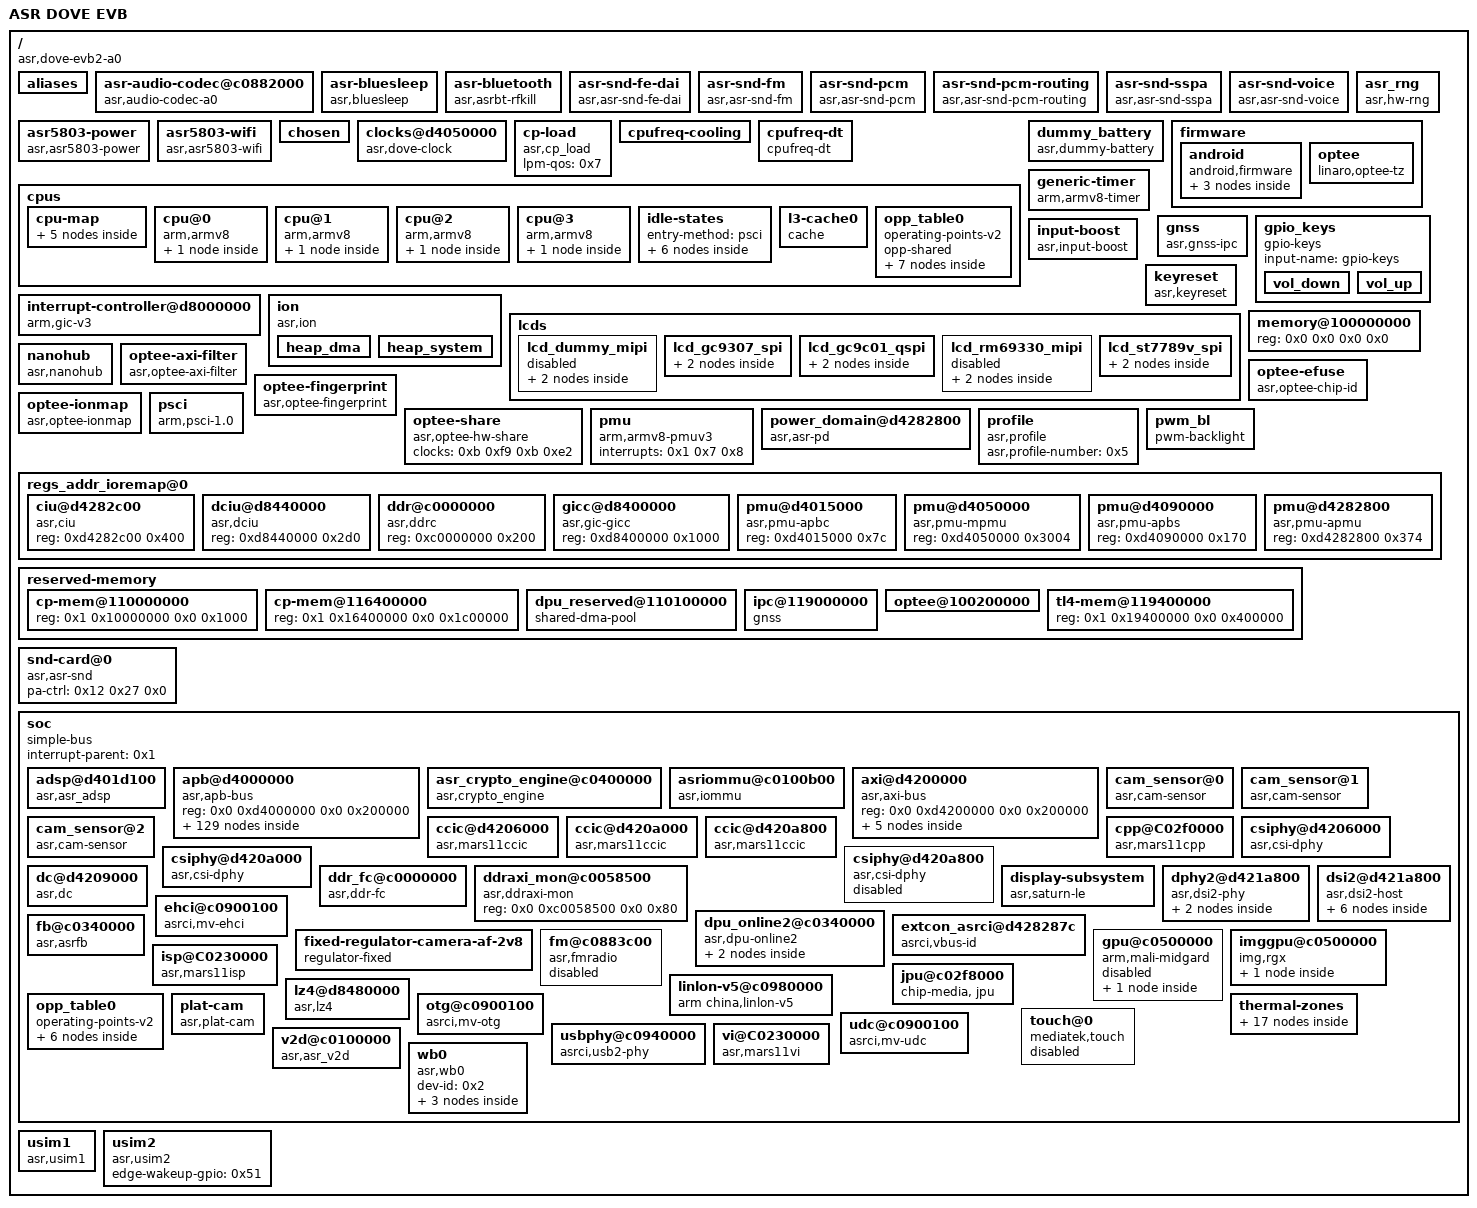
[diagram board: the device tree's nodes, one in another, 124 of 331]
/dts-v1/;

/ {
	#address-cells = <0x2>;
	#size-cells = <0x2>;
	board_id = <0x10000>;
	board_rev = <0x10081>;
	compatible = "asr,dove-evb2-a0", "asr,dove";
	interrupt-parent = <0x1>;
	model = "ASR DOVE EVB";

	aliases {
		i2c0 = "/soc/apb@d4000000/i2c@d4011000";
		i2c1 = "/soc/apb@d4000000/i2c@d4010800";
		i2c3 = "/soc/apb@d4000000/i2c@d4018800";
		serial0 = "/soc/apb@d4000000/uart@d4017000";
		serial1 = "/soc/apb@d4000000/uart@d4018000";
		serial2 = "/soc/apb@d4000000/uart@d4017800";
		serial3 = "/soc/apb@d4000000/uart@d4024000";
	};

	asr-audio-codec@c0882000 {
		compatible = "asr,audio-codec-a0", "syscon";
		interrupt-names = "hook_key", "jack_plug";
		interrupts = <0x0 0x6e 0x4 0x0 0x6f 0x4>;
		reg = <0x0 0xc0882000 0x0 0x21c 0x0 0xc088c000 0x0 0x100>;
		reg-names = "codec_ctrl", "aud_pmu";
		status = "ok";
	};

	asr-bluesleep {
		bluetooth-uart = <0x1>;
		bt_ext_wake = <0x12 0x7a 0x0>;
		bt_host_wake = <0x12 0x72 0x0>;
		compatible = "asr,bluesleep";
		status = "ok";
	};

	asr-bluetooth {
		compatible = "asr,asrbt-rfkill";
		status = "ok";
	};

	asr-snd-fe-dai {
		compatible = "asr,asr-snd-fe-dai";
	};

	asr-snd-fm {
		compatible = "asr,asr-snd-fm";
	};

	asr-snd-pcm {
		compatible = "asr,asr-snd-pcm";
	};

	asr-snd-pcm-routing {
		compatible = "asr,asr-snd-pcm-routing";
	};

	asr-snd-sspa {
		compatible = "asr,asr-snd-sspa";
	};

	asr-snd-voice {
		compatible = "asr,asr-snd-voice";
	};

	asr5803-power {
		bt_ldo_en_gpio = <0x73>;
		bt_wifi_reset = <0x12 0x6a 0x0>;
		compatible = "asr,asr5803-power";
		host_wake_bt_gpio = <0x7a>;
		ldo_1v2-supply = <0x48>;
		status = "ok";
		vldo11_wibpa_1v8-supply = <0x47>;
		wifi_host_wake_wlan = <0x6e>;
		wifi_ldo_en_gpio = <0x6f>;
	};

	asr5803-wifi {
		asr,is_dcs_mode = <0x1>;
		asr,is_dcxo_mode = <0x1>;
		compatible = "asr,asr5803-wifi";
		mac-address = [00 00 00 00 00 00];
		status = "ok";
	};

	asr_rng {
		compatible = "asr,hw-rng";
		status = "ok";
	};

	chosen {
		bootargs = "earlycon clk_ignore_unused log_buf_len=1M cma=16M@0x110400000 uart_dma printk.devkmsg=on";
		stdout-path = "serial0:115200n8";
	};

	clocks@d4050000 {
		#clock-cells = <0x1>;
		asr,keep_dbgclk_on;
		booton-clks = <0x28 0x3f>;
		compatible = "asr,dove-clock";
		interrupts = <0x0 0x60 0x4>;
		phandle = <0xb>;
		reg = <0x0 0xd4050000 0x0 0x209c 0x0 0xd4282800 0x0 0x400 0x0 0xd4015000 0x0 0x1000 0x0 0xd4090000 0x0 0x1000 0x0 0xd4282c00 0x0 0x400 0x0 0xd8440000 0x0 0x98 0x0 0xc0000000 0x0 0x4280>;
		reg-names = "mpmu", "apmu", "apbc", "apbs", "ciu", "dciu", "ddrc";
	};

	cp-load {
		compatible = "asr,cp_load";
		lpm-qos = <0x7>;
		status = "okay";
	};

	cpufreq-cooling {
		status = "ok";
	};

	cpufreq-dt {
		compatible = "cpufreq-dt";
		status = "okay";
	};

	cpus {
		#address-cells = <0x2>;
		#size-cells = <0x0>;

		cpu-map {

			cluster0 {

				core0 {
					cpu = <0x2>;
				};

				core1 {
					cpu = <0x3>;
				};

				core2 {
					cpu = <0x4>;
				};

				core3 {
					cpu = <0x5>;
				};
			};
		};

		cpu@0 {
			#cooling-cells = <0x2>;
			capacity-dmips-mhz = <0x400>;
			clocks = <0xb 0xb6>;
			compatible = "arm,armv8";
			cpu-idle-states = <0x6 0x7 0x8 0x9 0xa>;
			device_type = "cpu";
			dynamic-power-coefficient = <0x78>;
			enable-method = "psci";
			next-level-cache = <0xd>;
			operating-points-v2 = <0xc>;
			phandle = <0x2>;
			reg = <0x0 0x0>;

			l2-cache {
				next-level-cache = <0xe>;
				phandle = <0xd>;
			};
		};

		cpu@1 {
			#cooling-cells = <0x2>;
			capacity-dmips-mhz = <0x400>;
			clocks = <0xb 0xb6>;
			compatible = "arm,armv8";
			cpu-idle-states = <0x6 0x7 0x8 0x9 0xa>;
			device_type = "cpu";
			dynamic-power-coefficient = <0x78>;
			enable-method = "psci";
			next-level-cache = <0xf>;
			operating-points-v2 = <0xc>;
			phandle = <0x3>;
			reg = <0x0 0x100>;

			l2-cache {
				next-level-cache = <0xe>;
				phandle = <0xf>;
			};
		};

		cpu@2 {
			#cooling-cells = <0x2>;
			capacity-dmips-mhz = <0x400>;
			clocks = <0xb 0xb6>;
			compatible = "arm,armv8";
			cpu-idle-states = <0x6 0x7 0x8 0x9 0xa>;
			device_type = "cpu";
			dynamic-power-coefficient = <0x78>;
			enable-method = "psci";
			next-level-cache = <0x10>;
			operating-points-v2 = <0xc>;
			phandle = <0x4>;
			reg = <0x0 0x200>;

			l2-cache {
				next-level-cache = <0xe>;
				phandle = <0x10>;
			};
		};

		cpu@3 {
			#cooling-cells = <0x2>;
			capacity-dmips-mhz = <0x400>;
			clocks = <0xb 0xb6>;
			compatible = "arm,armv8";
			cpu-idle-states = <0x6 0x7 0x8 0x9 0xa>;
			device_type = "cpu";
			dynamic-power-coefficient = <0x78>;
			enable-method = "psci";
			next-level-cache = <0x11>;
			operating-points-v2 = <0xc>;
			phandle = <0x5>;
			reg = <0x0 0x300>;

			l2-cache {
				next-level-cache = <0xe>;
				phandle = <0x11>;
			};
		};

		idle-states {
			entry-method = "psci";

			chip-d1 {
				arm,psci-suspend-param = <0x2010455>;
				compatible = "arm,idle-state";
				entry-latency-us = <0x1f4>;
				exit-latency-us = <0x1f4>;
				local-timer-stop;
				min-residency-us = <0x7d0>;
				phandle = <0x9>;
				wakeup-latency-us = <0x3e8>;
			};

			chip-d1p {
				arm,psci-suspend-param = <0x2010355>;
				compatible = "arm,idle-state";
				entry-latency-us = <0x12c>;
				exit-latency-us = <0x12c>;
				local-timer-stop;
				min-residency-us = <0x4b0>;
				phandle = <0x8>;
				wakeup-latency-us = <0x258>;
			};

			chip-d2 {
				arm,psci-suspend-param = <0x2010555>;
				compatible = "arm,idle-state";
				entry-latency-us = <0x3e8>;
				exit-latency-us = <0x3e8>;
				local-timer-stop;
				min-residency-us = <0xfa0>;
				phandle = <0xa>;
				wakeup-latency-us = <0x7d0>;
			};

			cluster-mp2 {
				arm,psci-suspend-param = <0x1010055>;
				compatible = "arm,idle-state";
				entry-latency-us = <0xf0>;
				exit-latency-us = <0xf0>;
				local-timer-stop;
				min-residency-us = <0x3c0>;
				phandle = <0x7>;
				wakeup-latency-us = <0x1e0>;
			};

			cpu-c1 {
				arm,psci-suspend-param = <0x2>;
				compatible = "arm,idle-state";
				entry-latency-us = <0x19>;
				exit-latency-us = <0x19>;
				min-residency-us = <0x64>;
			};

			cpu-c2 {
				arm,psci-suspend-param = <0x10005>;
				compatible = "arm,idle-state";
				entry-latency-us = <0x5a>;
				exit-latency-us = <0x5a>;
				local-timer-stop;
				min-residency-us = <0x168>;
				phandle = <0x6>;
			};
		};

		l3-cache0 {
			compatible = "cache";
			phandle = <0xe>;
		};

		opp_table0 {
			compatible = "operating-points-v2";
			opp-shared;
			phandle = <0xc>;

			opp1000000000 {
				clock-latency-ns = <0x30d40>;
				opp-hz = <0x0 0x3b9aca00>;
				opp-microvolt = <0x16e360>;
			};

			opp1228000000 {
				clock-latency-ns = <0x30d40>;
				opp-hz = <0x0 0x4931cb00>;
				opp-microvolt = <0x16e360>;
			};

			opp1500000000 {
				clock-latency-ns = <0x30d40>;
				opp-hz = <0x0 0x59682f00>;
				opp-microvolt = <0x16e360>;
			};

			opp409000000 {
				clock-latency-ns = <0x30d40>;
				opp-hz = <0x0 0x1860d840>;
				opp-microvolt = <0xf4240>;
			};

			opp491000000 {
				clock-latency-ns = <0x30d40>;
				opp-hz = <0x0 0x1d4410c0>;
				opp-microvolt = <0xf4240>;
			};

			opp614000000 {
				clock-latency-ns = <0x30d40>;
				opp-hz = <0x0 0x2498e580>;
				opp-microvolt = <0x16e360>;
			};

			opp819000000 {
				clock-latency-ns = <0x30d40>;
				opp-hz = <0x0 0x30d0f2c0>;
				opp-microvolt = <0x16e360>;
			};
		};
	};

	dummy_battery {
		#cooling-cells = <0x2>;
		compatible = "asr,dummy-battery";
		status = "ok";
	};

	firmware {

		android {
			compatible = "android,firmware";

			fstab {
				compatible = "android,fstab";

				system {
					compatible = "android,system";
					dev = "/dev/block/platform/soc/d4200000.axi/d4281000.sdh/by-name/system";
					fsmgr_flags = "wait";
					mnt_flags = "ro,barrier=1";
					type = "ext4";
				};

				vendor {
					compatible = "android,vendor";
					dev = "/dev/block/platform/soc/d4200000.axi/d4281000.sdh/by-name/vendor";
					fsmgr_flags = "wait";
					mnt_flags = "ro,barrier=1";
					type = "ext4";
				};
			};
		};

		optee {
			compatible = "linaro,optee-tz";
			interrupts = <0x0 0x7d 0x4>;
			method = "smc";
		};
	};

	generic-timer {
		arm,no-tick-in-suspend;
		clock-frequency = <0x18cba80>;
		compatible = "arm,armv8-timer";
		interrupts = <0x1 0xd 0x8 0x1 0xe 0x8 0x1 0xb 0x8 0x1 0xa 0x8>;
	};

	gnss {
		clock-names = "ap2gnss_clk";
		clocks = <0xb 0x12a>;
		compatible = "asr,gnss-ipc";
		interrupt-names = "gnss_ipc", "gnss_wdt", "gnss_hostwake";
		interrupts = <0x0 0x32 0x4 0x0 0x65 0x4 0x0 0x66 0x4>;
		lna_1v8-supply = <0x42>;
		memory-region = <0x40>;
		reg = <0x0 0xd4282800 0x0 0x3bc 0x0 0xd6200000 0x0 0xfc 0x0 0xd401d200 0x0 0x14 0x0 0xd4015000 0x0 0x9c 0x0 0xd6000000 0x0 0x80000>;
		status = "ok";
		tcxo_1v8-supply = <0x41>;
	};

	gpio_keys {
		compatible = "gpio-keys";
		input-name = "gpio-keys";
		status = "ok";

		vol_down {
			debounce-interval = <0xf>;
			gpios = <0x12 0x3a 0x1>;
			label = "volume_down";
			linux,code = <0x72>;
			linux,input-type = <0x1>;
		};

		vol_up {
			debounce-interval = <0xf>;
			gpios = <0x12 0x39 0x1>;
			label = "volume_up";
			linux,code = <0x73>;
			linux,input-type = <0x1>;
		};
	};

	input-boost {
		compatible = "asr,input-boost";
		status = "okay";
	};

	interrupt-controller@d8000000 {
		#address-cells = <0x2>;
		#interrupt-cells = <0x3>;
		#size-cells = <0x2>;
		compatible = "arm,gic-v3";
		interrupt-controller;
		interrupts = <0x1 0x9 0x8>;
		phandle = <0x1>;
		reg = <0x0 0xd8000000 0x0 0x200000 0x0 0xd8080000 0x0 0x200000>;
	};

	ion {
		compatible = "asr,ion";

		heap_dma {
			heap-id = <0x4>;
			heap-name = "dma";
			heap-type = "ion_dma";
		};

		heap_system {
			heap-id = <0x0>;
			heap-name = "system";
			heap-type = "ion_system";
		};
	};

	keyreset {
		compatible = "asr,keyreset";
		keyreset-need-panic;
		keys-down = <0x74 0x73 0x72>;
		status = "okay";
	};

	lcds {
		status = "ok";

		lcd_dummy_mipi {
			burst-mode = <0x2>;
			dsi-color-format = "rgb888";
			dsi-lane-number = <0x4>;
			dsi-work-mode = <0x1>;
			eotp-enable = <0x0>;
			esd-check-enable = <0x0>;
			fps = <0x3c>;
			hbp = <0x64>;
			height = <0x640>;
			height-mm = <0x7e>;
			hfp = <0x63>;
			hsync = <0x4>;
			lane-number = <0x4>;
			phy-bit-clock = <0xde698>;
			phy-escape-clock = <0xcb20>;
			phy-freq = <0x98580>;
			rgb-mode = <0x3>;
			split-enable = <0x0>;
			status = "disabled";
			use-dcs-write;
			vbp = <0x1c>;
			vfp = <0x8c>;
			vsync = <0x6>;
			width = <0x2d0>;
			width-mm = <0x48>;
			work-mode = <0x0>;

			display-timings {

				timing0 {
					clock-frequency = <0x5dc0000>;
					hactive = <0x2d0>;
					hback-porch = <0x64>;
					hfront-porch = <0x63>;
					hsync-active = <0x1>;
					hsync-len = <0x4>;
					vactive = <0x640>;
					vback-porch = <0x1c>;
					vfront-porch = <0x8c>;
					vsync-active = <0x1>;
					vsync-len = <0x6>;
				};
			};
		};

		lcd_gc9307_spi {
			bg-color = <0xff>;
			cmd-initial-0 = [00 01 fe 00 00 01 ef 00 00 01 36 01 48 00 01 3a 01 05 00 01 86 01 98 00 01 89 01 03 00 01 8b 01 80 00 01 8d 01 22 00 01 8e 01 0f 00 01 e8 02 10 40 00 01 ff 01 62 00 01 99 01 3e 00 01 9d 01 4b 00 01 c3 01 34 00 01 c4 01 34 00 01 c9 01 2a 00 01 f0 06 87 08 09 08 06 29 00 01 f2 06 87 08 09 08 06 29 00 01 f1 06 c0 89 6a 3c fe 3f 00 01 f3 06 c0 89 6a 3c fe 3f 00 01 35 01 00 00 01 44 02 00 0a 78 01 11 00 00 01 29 00 14 01 2c 00];
			cmd-initial-1 = [00 01 fe 00 00 01 ef 00 00 01 36 01 48 00 01 3a 01 05 00 01 86 01 98 00 01 89 01 03 00 01 8b 01 80 00 01 8d 01 22 00 01 8e 01 0f 00 01 e8 02 20 40 00 01 ff 01 62 00 01 99 01 3e 00 01 9d 01 4b 00 01 c3 01 34 00 01 c4 01 34 00 01 c9 01 2a 00 01 f0 06 87 08 09 08 06 29 00 01 f2 06 87 08 09 08 06 29 00 01 f1 06 c0 89 6a 3c fe 3f 00 01 f3 06 c0 89 6a 3c fe 3f 00 01 35 01 00 00 01 44 02 00 1a 78 01 11 00 00 01 29 00 14 01 2c 00];
			cmd-initial-2 = [00 01 fe 00 00 01 ef 00 00 01 36 01 48 00 01 35 01 00 00 01 3a 01 05 00 01 86 01 98 00 01 89 01 13 00 01 8b 01 80 00 01 8d 01 33 00 01 8e 01 0f 00 01 ec 03 33 07 af 00 01 c9 01 05 00 01 e8 02 13 17 00 01 c3 01 10 00 01 c4 01 10 00 01 ff 01 62 00 01 99 01 3e 00 01 9d 01 4b 00 01 98 01 3e 00 01 9c 01 4b 00 01 f0 06 c7 08 08 08 05 2e 00 01 f2 06 c7 08 08 08 05 2e 00 01 f1 06 45 8f 6f 33 36 4f 00 01 f3 06 45 8f 6f 33 36 4f 00 01 44 02 00 0a 78 01 11 00 00 01 29 00 14 01 2c 00];
			cmd-initial-3 = [00 01 fe 00 00 01 ef 00 00 01 36 01 48 00 01 35 01 00 00 01 3a 01 05 00 01 86 01 98 00 01 89 01 33 00 01 8b 01 80 00 01 8d 01 33 00 01 8e 01 0f 00 01 ec 03 33 0c d1 00 01 c9 01 16 00 01 e8 02 12 00 00 01 c3 01 14 00 01 c4 01 08 00 01 ff 01 62 00 01 99 01 3e 00 01 9d 01 4b 00 01 98 01 3e 00 01 9c 01 4b 00 01 f0 06 c3 05 08 07 04 26 00 01 f2 06 c3 05 08 07 04 26 00 01 f1 06 3f 7f 6f 35 36 4f 00 01 f3 06 3f 7f 6f 35 36 4f 00 01 44 02 00 0a 78 01 11 00 00 01 29 00 14 01 2c 00];
			cmd-initial-4 = [00 01 fe 00 00 01 ef 00 00 01 36 01 48 00 01 3a 01 05 00 01 35 01 00 00 01 86 01 98 00 01 89 01 13 00 01 8b 01 80 00 01 8d 01 33 00 01 8e 01 0f 00 01 ec 03 33 07 af 00 01 c9 01 05 00 01 e8 02 13 17 00 01 c3 01 10 00 01 c4 01 10 00 01 ff 01 62 00 01 99 01 3e 00 01 9d 01 4b 00 01 98 01 3e 00 01 9c 01 4b 00 01 f0 06 c7 08 08 08 05 2e 00 01 f1 06 45 8f 6f 33 36 4f 00 01 f2 06 c7 08 08 08 05 2e 00 01 f3 06 45 8f 6f 33 36 4f 00 01 44 02 00 0a 78 01 11 00 00 01 29 00 00 01 2c 00];
			cmd-initial-5 = [00 01 fe 00 00 01 ef 00 00 01 36 01 48 00 01 3a 01 05 00 01 86 01 98 00 01 89 01 03 00 01 8b 01 80 00 01 8d 01 22 00 01 8e 01 0f 00 01 e8 02 12 00 00 01 c3 01 47 00 01 c4 01 28 00 01 c9 01 08 00 01 ff 01 62 00 01 99 01 3e 00 01 9d 01 4b 00 01 f0 06 07 0b 0c 0a 06 31 00 01 f2 06 07 07 04 06 06 21 00 01 f1 06 4a 78 76 33 2f af 00 01 f3 06 38 74 72 22 28 6f 00 01 35 01 00 00 01 44 02 00 0a 00 01 11 00 00 01 29 00 00 01 2c 00];
			cmd-initial-6 = [00 01 fe 00 00 01 ef 00 00 01 36 01 48 00 01 3a 01 05 00 01 86 01 98 00 01 89 01 33 00 01 8b 01 80 00 01 8d 01 33 00 01 8e 01 0f 00 01 ec 03 33 0c d1 00 01 c9 01 16 00 01 e8 02 13 17 00 01 c3 01 22 00 01 c4 01 16 00 01 ff 01 62 00 01 99 01 3e 00 01 9d 01 4b 00 01 98 01 3e 00 01 9c 01 4b 00 01 f0 06 c3 05 08 07 04 26 00 01 f2 06 c3 05 08 07 04 26 00 01 f1 06 3f 7f 6f 35 36 4f 00 01 f3 06 3f 7f 6f 35 36 4f 00 01 35 01 00 00 01 44 02 00 0a 78 01 11 00 00 01 29 00 14 01 2c 00];
			cmd-read-id = [00 01 da 01 00 00 01 db 01 93 00 01 dc 01 07 00 01 04 03 07 93 00];
			cmd-set-window-240x240 = <0x12a04 0xef 0x12b04 0xef 0x12c00>;
			cmd-set-window-240x280 = <0x12a04 0xef 0x12b04 0x13012b 0x12c00>;
			cmd-set-window-240x284 = <0x12a04 0xef 0x12b04 0x11b 0x12c00>;
			cmd-set-window-240x296 = <0x12a04 0xef 0x12b04 0x127 0x12c00>;
			cmd-set-window-240x320 = <0x12a04 0xef 0x12b04 0x13f 0x12c00>;
			cmd-sleep-in = <0x14012800 0x78011000>;
			cmd-sleep-out = <0x78011100 0x78012900>;
			custom-cmd-set-window = <0x0>;
			data-lane-number = <0x1>;
			device-id = <0x0>;
			endian = <0x1>;
			format = "rgb565";
			height-mm = <0x7e>;
			interface-id = <0x1>;
			line-number = <0x4>;
			mclk-freq = <0x124f8000>;
			reset-sequence = <0x140178>;
			sample-edge = <0x0>;
			spi-rclk-freq = <0x177000>;
			spi-wclk-freq = <0x3197500>;
			te-en = <0x1>;
			te-polarity = <0x0>;
			width-mm = <0x48>;

			display-timings {

				timing0 {
					clock-frequency = <0x4a6214>;
					hactive = <0xf0>;
					hback-porch = <0x64>;
					hfront-porch = <0x63>;
					hsync-active = <0x1>;
					hsync-len = <0x4>;
					vactive = <0xf0>;
					vback-porch = <0x8>;
					vfront-porch = <0x8>;
					vsync-active = <0x1>;
					vsync-len = <0x6>;
				};
			};
		};

		lcd_gc9c01_qspi {
			bg-color = <0xff>;
			cmd-initial = [00 04 02 00 fe 00 00 00 04 02 00 ef 00 00 00 04 02 00 80 00 01 11 00 04 02 00 81 00 01 70 00 04 02 00 82 00 01 09 00 04 02 00 83 00 01 03 00 04 02 00 84 00 01 20 00 04 02 00 89 00 01 10 00 04 02 00 8a 00 01 4f 00 04 02 00 8b 00 01 08 00 04 02 00 8c 00 01 59 00 04 02 00 8d 00 01 51 00 04 02 00 36 00 01 00 00 04 02 00 3a 00 01 05 00 04 02 00 ec 00 01 77 00 04 02 00 74 00 06 01 80 00 00 00 00 00 04 02 00 98 00 01 3e 00 04 02 00 99 00 01 3e 00 04 02 00 c3 00 01 3a 00 04 02 00 c4 00 01 16 00 04 02 00 a1 00 02 01 04 00 04 02 00 a2 00 02 01 04 00 04 02 00 cb 00 01 02 00 04 02 00 7c 00 02 b6 26 00 04 02 00 ac 00 01 24 00 04 02 00 f6 00 01 80 00 04 02 00 b5 00 02 09 09 00 04 02 00 60 00 04 38 0b 5b 56 00 04 02 00 63 00 04 3a e0 5b 56 00 04 02 00 64 00 06 38 0d 72 dd 5b 56 00 04 02 00 66 00 06 38 11 72 e1 5b 56 00 04 02 00 68 00 07 3b 08 08 00 08 29 5b 00 04 02 00 6e 00 20 00 00 00 07 01 13 11 0b 09 16 15 1d 1e 00 00 00 00 00 00 1e 1d 15 16 0a 0c 12 14 02 08 00 00 00 00 04 02 00 be 00 01 11 00 04 02 00 6c 00 07 cc 0c cc 84 cc 04 50 00 04 02 00 7d 00 01 72 00 04 02 00 7e 00 01 38 00 04 02 00 70 00 0a 02 03 09 05 0c 06 09 05 0c 06 00 04 02 00 90 00 04 06 06 05 06 00 04 02 00 93 00 03 45 ff 00 00 04 02 00 f0 00 06 46 0b 0f 0a 10 3f 00 04 02 00 f1 00 06 52 9a 4f 36 37 ff 00 04 02 00 f2 00 06 46 0b 0f 0a 10 3f 00 04 02 00 f3 00 06 52 9a 4f 36 37 ff 00 04 02 00 35 00 01 00 00 04 02 00 44 00 02 00 25 00 04 02 00 b4 00 02 0a 50 00 04 02 00 fb 00 02 00 00 78 04 02 00 11 00 00 14 04 02 00 29 00 00];
			cmd-set-window = [00 04 02 00 2a 00 04 00 00 01 67 00 04 02 00 2b 00 04 00 00 01 67];
			cmd-sleep-in = [78 04 02 00 28 00 00 96 04 02 00 10 00 00];
			cmd-sleep-out = [78 04 02 00 11 00 00 64 04 02 00 29 00 00];
			cmd-start = [00 04 32 00 2c 00 00];
			data-lane-number = <0x1>;
			device-id = <0x0>;
			endian = <0x1>;
			format = "rgb565";
			frame-sync;
			height-mm = <0x7e>;
			interface-id = <0x1>;
			line-number = <0x4>;
			mclk-freq = <0x124f8000>;
			qspi;
			reset-sequence = [01 78 00 64 01 78];
			sample-edge = <0x0>;
			spi-rclk-freq = <0x177000>;
			spi-wclk-freq = <0x30d4000>;
			te-en = <0x0>;
			te-polarity = <0x0>;
			width-mm = <0x48>;

			display-timings {

				timing0 {
					clock-frequency = <0x3197500>;
					hactive = <0x168>;
					hback-porch = <0x64>;
					hfront-porch = <0x63>;
					hsync-active = <0x1>;
					hsync-len = <0x4>;
					vactive = <0x168>;
					vback-porch = <0x8>;
					vfront-porch = <0x8>;
					vsync-active = <0x1>;
					vsync-len = <0x6>;
				};
			};
		};

		lcd_rm69330_mipi {
			backlight = <0x43>;
			bit-clk = <0x13de4355 0x13de4355>;
			burst-mode = <0x2>;
			dsi-color-format = "rgb888";
			dsi-lane-number = <0x1>;
			dsi-work-mode = <0x0>;
			eotp-enable = <0x0>;
			esd-check-enable = <0x0>;
			fps = <0x3c>;
			hbp = <0x28>;
			height = <0x1c6>;
			height-mm = <0x7e>;
			hfp = <0x14>;
			hsync = <0xa>;
			initial-command = <0x15010002 0xfe071501 0x21504 0x15010002 0xfe001501 0x23500 0x15010002 0x3a771501 0x25100 0x39010005 0x2a000e01 0xd3390100 0x52b0000 0x1c50501 0x78011105 0x1140129>;
			lane-number = <0x1>;
			oled;
			phy-bit-clock = <0xde698>;
			phy-escape-clock = <0xcb20>;
			phy-freq = <0x61a80>;
			read-id-command = [37 01 00 01 01 14 01 00 01 0a];
			rgb-mode = <0x3>;
			sleep-in-command = [05 01 00 01 28 05 01 78 01 10];
			sleep-out-command = [05 01 78 01 11 05 01 14 01 29];
			split-enable = <0x0>;
			status = "disabled";
			use-dcs-write;
			vbp = <0xc>;
			vfp = <0x14>;
			vsync = <0xa>;
			width = <0x1c6>;
			width-mm = <0x48>;
			work-mode = <0x1>;

			display-timings {

				timing0 {
					clock-frequency = <0xedf300>;
					hactive = <0x1c6>;
					hback-porch = <0x28>;
					hfront-porch = <0x14>;
					hsync-active = <0x1>;
					hsync-len = <0xa>;
					vactive = <0x1c6>;
					vback-porch = <0xc>;
					vfront-porch = <0x14>;
					vsync-active = <0x1>;
					vsync-len = <0xa>;
				};
			};
		};

		lcd_st7789v_spi {
			bg-color = <0xff>;
			cmd-initial = [78 01 11 00 78 01 36 01 00 00 01 3a 01 06 00 01 35 01 00 00 01 c7 01 00 00 01 cc 01 09 00 01 b2 05 0c 0c 00 33 33 00 01 b7 01 35 00 01 bb 01 19 00 01 c0 01 2c 00 01 c2 01 01 00 01 c3 01 12 00 01 c4 01 20 00 01 c6 01 0f 00 01 d0 02 a4 a1 00 01 e0 0e d0 03 0e 11 17 1f 4c 53 5b 1a 16 13 25 28 00 01 e1 0e d0 02 0e 11 16 1e 4a 36 56 1a 15 14 26 28 00 01 29 00];
			cmd-read-id = [00 01 da 01 85 00 01 db 01 85 00 01 dc 01 52 00 01 04 03 52 85 85];
			cmd-set-window = <0x12a04 0xef 0x12b04 0xef 0x12c00>;
			cmd-sleep-in = <0x14012800 0x78011000>;
			cmd-sleep-out = <0x78011100 0x14012900>;
			data-lane-number = <0x1>;
			device-id = <0x0>;
			endian = <0x1>;
			format = "rgb666";
			height-mm = <0x7e>;
			interface-id = <0x1>;
			line-number = <0x4>;
			mclk-freq = <0x124f8000>;
			reset-sequence = <0x140178>;
			sample-edge = <0x0>;
			spi-rclk-freq = <0x177000>;
			spi-wclk-freq = <0x30d4000>;
			te-en = <0x1>;
			te-polarity = <0x0>;
			width-mm = <0x48>;

			display-timings {

				timing0 {
					clock-frequency = <0x3197500>;
					hactive = <0xf0>;
					hback-porch = <0x64>;
					hfront-porch = <0x63>;
					hsync-active = <0x1>;
					hsync-len = <0x4>;
					vactive = <0xf0>;
					vback-porch = <0x8>;
					vfront-porch = <0x8>;
					vsync-active = <0x1>;
					vsync-len = <0x6>;
				};
			};
		};
	};

	memory@100000000 {
		device_type = "memory";
		reg = <0x0 0x0 0x0 0x0>;
	};

	nanohub {
		compatible = "asr,nanohub";
		gpi-count = <0x3>;
		gpi-list = <0x4a 0x4b 0x4c>;
		pinctrl-0 = <0x45>;
		pinctrl-names = "sh_i2c";
		sensor_3v3-supply = <0x44>;
		status = "ok";
	};

	optee-axi-filter {
		compatible = "asr,optee-axi-filter";
		status = "ok";
	};

	optee-efuse {
		compatible = "asr,optee-chip-id";
		status = "ok";
	};

	optee-fingerprint {
		compatible = "asr,optee-fingerprint";
		status = "ok";
	};

	optee-ionmap {
		compatible = "asr,optee-ionmap";
		status = "ok";
	};

	optee-share {
		clock-names = "aes", "ssp2";
		clocks = <0xb 0xf9 0xb 0xe2>;
		compatible = "asr,optee-hw-share";
		status = "ok";
	};

	pmu {
		compatible = "arm,armv8-pmuv3";
		interrupts = <0x1 0x7 0x8>;
	};

	power_domain@d4282800 {
		#power-domain-cells = <0x1>;
		asr-pd,pwr-blk-tmr = <0x10f3f0f>;
		clock-names = "vpu", "gpu", "audio", "ispfnc", "ispbus", "ispsc2ahb", "cppfnc", "ccicfnc", "dpuhclk", "dpumclk", "dpupxclk", "dpuescclk", "dpubitclk";
		clocks = <0xb 0xed 0xb 0xeb 0xb 0x10e 0xb 0xff 0xb 0xfe 0xb 0x101 0xb 0x123 0xb 0x100 0xb 0xf1 0xb 0xf2 0xb 0xf0 0xb 0xf5 0xb 0xf6>;
		compatible = "asr,asr-pd";
		phandle = <0x22>;
		reg = <0x0 0xd4282800 0x0 0x400>;
		status = "ok";
	};

	profile {
		asr,profile-number = <0x5>;
		compatible = "asr,profile";
	};

	psci {
		compatible = "arm,psci-1.0";
		cpu_off = <0x84000002>;
		cpu_on = <0xc4000003>;
		cpu_suspend = <0xc4000001>;
		method = "smc";
	};

	pwm_bl {
		brightness-levels = <0x0 0x1 0x2 0x3 0x4 0x5 0x6 0x7 0x8 0x9 0xa 0xb 0xc 0xd 0xe 0xf 0x10 0x11 0x12 0x13 0x14 0x15 0x16 0x17 0x18 0x19 0x1a 0x1b 0x1c 0x1d 0x1e 0x1f 0x20 0x21 0x22 0x23 0x24 0x25 0x26 0x27 0x28 0x29 0x2a 0x2b 0x2c 0x2d 0x2e 0x2f 0x30 0x31 0x32 0x33 0x34 0x35 0x36 0x37 0x38 0x39 0x3a 0x3b 0x3c 0x3d 0x3e 0x3f 0x40 0x41 0x42 0x43 0x44 0x45 0x46 0x47 0x48 0x49 0x4a 0x4b 0x4c 0x4d 0x4e 0x4f 0x50 0x51 0x52 0x53 0x54 0x55 0x56 0x57 0x58 0x59 0x5a 0x5b 0x5c 0x5d 0x5e 0x5f 0x60 0x61 0x62 0x63 0x64 0x65 0x66 0x67 0x68 0x69 0x6a 0x6b 0x6c 0x6d 0x6e 0x6f 0x70 0x71 0x72 0x73 0x74 0x75 0x76 0x77 0x78 0x79 0x7a 0x7b 0x7c 0x7d 0x7e 0x7f 0x80 0x81 0x82 0x83 0x84 0x85 0x86 0x87 0x88 0x89 0x8a 0x8b 0x8c 0x8d 0x8e 0x8f 0x90 0x91 0x92 0x93 0x94 0x95 0x96 0x97 0x98 0x99 0x9a 0x9b 0x9c 0x9d 0x9e 0x9f 0xa0 0xa1 0xa2 0xa3 0xa4 0xa5 0xa6 0xa7 0xa8 0xa9 0xaa 0xab 0xac 0xad 0xae 0xaf 0xb0 0xb1 0xb2 0xb3 0xb4 0xb5 0xb6 0xb7 0xb8 0xb9 0xba 0xbb 0xbc 0xbd 0xbe 0xbf 0xc0 0xc1 0xc2 0xc3 0xc4 0xc5 0xc6 0xc7 0xc8 0xc9 0xca 0xcb 0xcc 0xcd 0xce 0xcf 0xd0 0xd1 0xd2 0xd3 0xd4 0xd5 0xd6 0xd7 0xd8 0xd9 0xda 0xdb 0xdc 0xdd 0xde 0xdf 0xe0 0xe1 0xe2 0xe3 0xe4 0xe5 0xe6 0xe7 0xe8 0xe9 0xea 0xeb 0xec 0xed 0xee 0xef 0xf0 0xf1 0xf2 0xf3 0xf4 0xf5 0xf6 0xf7 0xf8 0xf9 0xfa 0xfb 0xfc 0xfd 0xfe 0xff>;
		compatible = "pwm-backlight";
		default-brightness-level = <0x80>;
		phandle = <0x43>;
		pwms = <0x3f 0x0 0x4ebc>;
		status = "ok";
	};

	regs_addr_ioremap@0 {
		#address-cells = <0x1>;
		#size-cells = <0x1>;
		ranges = <0x0 0x0 0x0 0xffffffff>;

		ciu@d4282c00 {
			compatible = "asr,ciu", "syscon";
			reg = <0xd4282c00 0x400>;
		};

		dciu@d8440000 {
			compatible = "asr,dciu", "syscon";
			reg = <0xd8440000 0x2d0>;
		};

		ddr@c0000000 {
			compatible = "asr,ddrc", "syscon";
			reg = <0xc0000000 0x200>;
		};

		gicc@d8400000 {
			compatible = "asr,gic-gicc", "syscon";
			reg = <0xd8400000 0x1000>;
		};

		pmu@d4015000 {
			compatible = "asr,pmu-apbc", "syscon";
			reg = <0xd4015000 0x7c>;
		};

		pmu@d4050000 {
			compatible = "asr,pmu-mpmu", "syscon";
			reg = <0xd4050000 0x3004>;
		};

		pmu@d4090000 {
			compatible = "asr,pmu-apbs", "syscon";
			reg = <0xd4090000 0x170>;
		};

		pmu@d4282800 {
			compatible = "asr,pmu-apmu", "syscon";
			reg = <0xd4282800 0x374>;
		};
	};

	reserved-memory {
		#address-cells = <0x2>;
		#size-cells = <0x2>;
		ranges;

		cp-mem@110000000 {
			reg = <0x1 0x10000000 0x0 0x1000>;
		};

		cp-mem@116400000 {
			reg = <0x1 0x16400000 0x0 0x1c00000>;
		};

		dpu_reserved@110100000 {
			compatible = "shared-dma-pool";
			no-map;
			phandle = <0x29>;
			reg = <0x1 0x10100000 0x0 0x60000>;
		};

		ipc@119000000 {
			compatible = "gnss";
			no-map;
			phandle = <0x40>;
			reg = <0x1 0x19000000 0x0 0x100000>;
		};

		optee@100200000 {
			no-map;
			reg = <0x1 0x200000 0x0 0xe00000>;
		};

		tl4-mem@119400000 {
			reg = <0x1 0x19400000 0x0 0x400000>;
		};
	};

	snd-card@0 {
		compatible = "asr,asr-snd";
		pa-ctrl = <0x12 0x27 0x0>;
	};

	soc {
		#address-cells = <0x2>;
		#size-cells = <0x2>;
		compatible = "simple-bus";
		interrupt-parent = <0x1>;
		ranges;

		adsp@d401d100 {
			clock-names = "adspcore", "adspipc", "adsp_pll_d10", "adsp_pll_d100";
			clocks = <0xb 0x10e 0xb 0x10f 0xb 0x137 0xb 0x161>;
			compatible = "asr,asr_adsp";
			interrupt-names = "adsp_ipc_irq", "adsp_wakeup";
			interrupts = <0x0 0x1e 0x4 0x0 0x51 0x4>;
			reg = <0x0 0xd401d100 0x0 0x100 0x0 0xc088c000 0x0 0x1000 0x0 0xd4282800 0x0 0x400 0x0 0xc0880000 0x0 0x200 0x0 0xd4090000 0x0 0x200>;
			reg-names = "ipcreg", "bootc", "pmuap", "aud_sysctrl", "apb_spare";
			status = "okay";
		};

		apb@d4000000 {
			#address-cells = <0x1>;
			#size-cells = <0x1>;
			compatible = "asr,apb-bus", "simple-bus";
			ranges = <0x0 0x0 0x0 0xffffffff>;
			reg = <0x0 0xd4000000 0x0 0x200000>;

			acipc@d401d000 {
				binding-core-range = <0x4 0x7>;
				compatible = "mrvl,mmp-acipc";
				interrupt-names = "IPC_AP_DATAACK";
				interrupts = <0x0 0x1d 0x4>;
				reg = <0xd401d000 0x100>;
				status = "okay";
			};

			asr-cpufreq-cooling {
				compatible = "asr,cpufreq-cooling";
				status = "ok";
			};

			asr-gpufreq-cooling {
				compatible = "asr,gpufreq-cooling";
				gpu_device = "img,rgx";
				status = "ok";
			};

			asr-pa-cooling {
				compatible = "asr,cp-pa-cooling";
				pa-power-reduce-level0 = <0x0>;
				pa-power-reduce-level1 = <0x2>;
				pa-power-reduce-level2 = <0x4>;
				pa-power-reduce-level3 = <0x6>;
				pa-power-reduce-level4 = <0x8>;
				pa-power-reduce-level5 = <0xa>;
				status = "ok";
			};

			coresight@d5000000 {
				#address-cells = <0x1>;
				#size-cells = <0x1>;
				clock-names = "DBGCLK";
				clocks = <0xb 0x118>;
				compatible = "asr,coresight";
				ranges;
				reg = <0xd5000000 0x1000000>;
				status = "ok";
				topology = <0x4>;

				cs_cti@d5420000 {
					compatible = "asr,coresight-cti";
					reg = <0xd5420000 0x10000 0xd5520000 0x10000 0xd5620000 0x10000 0xd5720000 0x10000>;
				};

				cs_dbg@d5410000 {
					compatible = "asr,coresight-dbg";
					reg = <0xd5410000 0x10000 0xd5510000 0x10000 0xd5610000 0x10000 0xd5710000 0x10000>;
				};

				cs_pmu@d5430000 {
					compatible = "asr,coresight-pmu";
					reg = <0xd5430000 0x10000 0xd5530000 0x10000 0xd5630000 0x10000 0xd5730000 0x10000>;
				};
			};

			edgewakeup@d4019800 {
				compatible = "asr,edge-wakeup";
				interrupts = <0x0 0x27 0x4>;
				reg = <0xd4019800 0x10 0xd401e000 0x400>;
				status = "ok";
			};

			gpio@d4019000 {
				#address-cells = <0x1>;
				#gpio-cells = <0x2>;
				#size-cells = <0x1>;
				clocks = <0xb 0xd1>;
				compatible = "asr,asr-gpio";
				gpio-controller;
				interrupt-names = "gpio_mux";
				interrupts = <0x0 0x25 0x4>;
				phandle = <0x12>;
				ranges;
				reg = <0xd4019000 0x800>;

				gpio0 {
					gpio-ranges = <0x26 0x0 0x37 0x20>;
					reg-offset = <0x0>;
				};

				gpio1 {
					gpio-ranges = <0x26 0x0 0x57 0x17>;
					reg-offset = <0x4>;
				};

				gpio2 {
					gpio-ranges = <0x26 0x3 0x6e 0x1d>;
					reg-offset = <0x8>;
				};

				gpio3 {
					gpio-ranges = <0x26 0x0 0x8b 0x3 0x26 0x1c 0x34 0x1>;
					reg-offset = <0x100>;
				};
			};

			i2c@d4010800 {
				#address-cells = <0x1>;
				#size-cells = <0x0>;
				asr,adapter-id = <0x1>;
				asr,apb_clock = <0x3197500>;
				asr,dma-disable;
				asr,i2c-fast-mode;
				asr,i2c-lcr = <0x82c469f>;
				asr,i2c-wcr = <0x142a>;
				clocks = <0xb 0xc9>;
				compatible = "asr,asr-i2c";
				dma-names = "rx", "tx";
				dmas = <0x23 0x10 0x1 0x23 0xf 0x1>;
				interrupts = <0x0 0x15 0x4>;
				lpm-qos = <0x7>;
				reg = <0xd4010800 0x38>;
				status = "ok";
			};

			i2c@d4011000 {
				#address-cells = <0x1>;
				#size-cells = <0x0>;
				asr,adapter-id = <0x0>;
				asr,apb_clock = <0x3197500>;
				asr,dma-disable;
				asr,i2c-fast-mode;
				asr,i2c-lcr = <0x82c469f>;
				asr,i2c-wcr = <0x142a>;
				clocks = <0xb 0xc8>;
				compatible = "asr,asr-i2c";
				dma-names = "rx", "tx";
				dmas = <0x23 0x8 0x1 0x23 0x7 0x1>;
				interrupts = <0x0 0x14 0x4>;
				lpm-qos = <0x7>;
				reg = <0xd4011000 0x38>;
				status = "ok";
			};

			i2c@d4013800 {
				#address-cells = <0x1>;
				#size-cells = <0x0>;
				asr,adapter-id = <0x2>;
				asr,apb_clock = <0x3197500>;
				asr,dma-disable;
				asr,i2c-fast-mode;
				asr,i2c-lcr = <0x82c469f>;
				asr,i2c-wcr = <0x142a>;
				clocks = <0xb 0xca>;
				compatible = "asr,asr-i2c";
				dma-names = "rx", "tx";
				dmas = <0x23 0xe 0x1 0x23 0xd 0x1>;
				interrupts = <0x0 0x16 0x4>;
				lpm-qos = <0x7>;
				reg = <0xd4013800 0x38>;
				status = "ok";

				aw36515@63 {
					compatible = "awinic,leds_aw36515";
					reg = <0x63>;
					status = "okay";
				};
			};

			i2c@d4018800 {
				#address-cells = <0x1>;
				#size-cells = <0x0>;
				asr,adapter-id = <0x3>;
				asr,apb_clock = <0x3197500>;
				asr,clk-always-on;
				asr,dma-disable;
				asr,i2c-apdcp;
				asr,i2c-clk-rate = <0x1e84800>;
				asr,i2c-fast-mode;
				asr,i2c-lcr = <0x82c469f>;
				asr,i2c-master-code = [0e];
				asr,i2c-wcr = <0x142a>;
				clocks = <0xb 0xcb>;
				compatible = "asr,asr-i2c";
				dma-names = "rx", "tx";
				dmas = <0x23 0x12 0x1 0x23 0x11 0x1>;
				interrupts = <0x0 0x17 0x4>;
				lpm-qos = <0x7>;
				reg = <0xd4018800 0x38 0xd40b0300 0x4>;
				status = "ok";

				pm813@30 {
					asr,pm813-irq-write-clear;
					asr,pmic-bd-cfg = <0x1 0x25 0x8 0x0 0x1 0x35 0x8 0x0 0x1 0x22 0x18 0x10 0x1 0x32 0x18 0x10 0x1 0x39 0x1 0x1 0x0 0xec 0xc 0x8 0x1 0x21 0x7f 0x0 0x1 0x31 0x7f 0x5a 0x1 0x27 0xff 0x71 0x1 0x8d 0x30 0x20>;
					compatible = "asr,pm813";
					interrupt-parent = <0x1>;
					interrupts = <0x0 0x2b 0x4>;
					reg = <0x30>;
					status = "ok";

					battery {
					};

					charger {
						#cooling-cells = <0x2>;
						battery-in-current-limit-level0 = <0x1f4>;
						battery-in-current-limit-level1 = <0x1f4>;
						battery-in-current-limit-level2 = <0x1c2>;
						battery-in-current-limit-level3 = <0x15e>;
						battery-in-current-limit-level4 = <0xfa>;
						battery-in-current-limit-level5 = <0x96>;
						charger-temp-demand = <0x46>;
						charger-temp-limit = <0x64>;
						compatible = "asr,pm813-charger";
						status = "ok";

						battery {
							bat-charge-current-limit = <0x0 0x1f4 0x1f4 0x1f4 0x0>;
							bat-force-power-off-th = <0xd48>;
							bat-ir = <0xc8>;
							bat-monitor-intval = <0x2d>;
							bat-temp-range = <0x111 0x11b 0x139 0x143>;
							bat-volt-low-th = <0xe38>;
							bat-voltage = <0x10cc>;
							battery_ntc_exist = <0x1>;
							capacity-increase-thr = <0x14>;
							capacity-volt-table = <0xd48 0xd71 0xdba 0xdf0 0xe13 0xe21 0xe28 0xe2e 0xe32 0xe35 0xe39 0xe3d 0xe42 0xe49 0xe4f 0xe56 0xe5d 0xe62 0xe66 0xe6a 0xe6f 0xe72 0xe76 0xe7a 0xe7d 0xe81 0xe84 0xe87 0xe89 0xe8a 0xe8c 0xe8e 0xe90 0xe92 0xe94 0xe97 0xe99 0xe9c 0xe9f 0xea2 0xea6 0xeaa 0xead 0xeb1 0xeb5 0xeb9 0xebe 0xec2 0xec7 0xecc 0xed1 0xed7 0xedd 0xee3 0xeea 0xef1 0xef8 0xeff 0xf06 0xf0d 0xf14 0xf1b 0xf22 0xf29 0xf30 0xf38 0xf40 0xf47 0xf4e 0xf54 0xf5a 0xf61 0xf6c 0xf79 0xf87 0xf94 0xf9e 0xfa6 0xfb0 0xfb9 0xfc4 0xfcf 0xfd9 0xfe4 0xfef 0xffb 0x1006 0x1011 0x101c 0x1028 0x1034 0x103f 0x104c 0x1059 0x1066 0x1073 0x1081 0x1090 0x10a1 0x10ad 0x10b4>;
							capacity-volt-table-start = <0x0>;
							capacity-volt-table-step = <0x1>;
							cc-limit = <0x190>;
							chg-eoc = <0x32>;
							chg-tout = <0xf0>;
							cv-limit = <0x10fe>;
							ntc-volt-table = <0x621ec 0x44c00 0x30e08 0x233ac 0x19bb8 0x1304c 0xe38a 0xabfe 0x8354 0x6540 0x4eca 0x3de0 0x30fc 0x2710 0x1f65 0x196a 0x14b5 0x10fc 0xe04 0xba2 0x9b6 0x826 0x6e0 0x5d4 0x4f6 0x43f 0x3a5 0x325 0x2b9>;
							ntc-volt-table-start = <0xe9>;
							ntc-volt-table-step = <0x5>;
							prechg-current = <0x96>;
							prechg-tout = <0x3c>;
							recharge-voltage-thr = <0x109a>;
						};
					};

					debugfs {
						compatible = "asr,pm813-debugfs";
					};

					dvc {
						compatible = "asr,pm813-dvc";
						status = "ok";
					};

					gpadc {
						compatible = "asr,pm813-gpadc";
					};

					keypad_led {
						compatible = "asr,pm813-kpled";
						status = "disable";
					};

					led {
						boot-on;
						compatible = "asr,pm813-led";
					};

					onkey {
						compatible = "asr,pm813-onkey";
						disable-long-onkey-rst = <0x0>;
						long-onkey-press-time = <0xa>;
						long-onkey-type = <0x1>;
						onkey-press-debounce-time = <0x1e>;
					};

					pmic-thermal {
						#thermal-sensor-cells = <0x1>;
						compatible = "asr,pm813-thermal";
						phandle = <0x3a>;
						status = "ok";
					};

					regulator-buck1 {
						compatible = "asr,pm813-buck1";
						regulator-always-on;
						regulator-boot-on;
						regulator-max-microvolt = <0x3c45b0>;
						regulator-min-microvolt = <0x927c0>;
					};

					regulator-buck2 {
						compatible = "asr,pm813-buck2";
						regulator-always-on;
						regulator-boot-on;
						regulator-max-microvolt = <0x3c45b0>;
						regulator-min-microvolt = <0x927c0>;
					};

					regulator-buck3 {
						compatible = "asr,pm813-buck3";
						regulator-max-microvolt = <0x3c45b0>;
						regulator-min-microvolt = <0x927c0>;
						status = "disabled";
					};

					regulator-ldo1 {
						compatible = "asr,pm813-ldo1";
						phandle = <0x2c>;
						regulator-always-on;
						regulator-max-microvolt = <0x325aa0>;
						regulator-min-microvolt = <0x124f80>;
					};

					regulator-ldo10 {
						compatible = "asr,pm813-ldo10";
						phandle = <0x3c>;
						regulator-max-microvolt = <0x325aa0>;
						regulator-min-microvolt = <0x124f80>;
					};

					regulator-ldo11 {
						compatible = "asr,pm813-ldo11";
						phandle = <0x48>;
						regulator-always-on;
						regulator-boot-on;
						regulator-max-microvolt = <0x325aa0>;
						regulator-min-microvolt = <0x124f80>;
					};

					regulator-ldo12 {
						compatible = "asr,pm813-ldo12";
						phandle = <0x44>;
						regulator-max-microvolt = <0x325aa0>;
						regulator-min-microvolt = <0x124f80>;
					};

					regulator-ldo13 {
						compatible = "asr,pm813-ldo13";
						phandle = <0x3d>;
						regulator-max-microvolt = <0x325aa0>;
						regulator-min-microvolt = <0x19f0a0>;
					};

					regulator-ldo2 {
						compatible = "asr,pm813-ldo2";
						regulator-always-on;
						regulator-boot-on;
						regulator-max-microvolt = <0x325aa0>;
						regulator-min-microvolt = <0x124f80>;
					};

					regulator-ldo3 {
						compatible = "asr,pm813-ldo3";
						regulator-max-microvolt = <0x325aa0>;
						regulator-min-microvolt = <0x124f80>;
						status = "disabled";
					};

					regulator-ldo4 {
						compatible = "asr,pm813-ldo4";
						phandle = <0x47>;
						regulator-max-microvolt = <0x325aa0>;
						regulator-min-microvolt = <0x124f80>;
					};

					regulator-ldo5 {
						compatible = "asr,pm813-ldo5";
						phandle = <0x41>;
						regulator-always-on;
						regulator-boot-on;
						regulator-max-microvolt = <0x325aa0>;
						regulator-min-microvolt = <0x19f0a0>;
					};

					regulator-ldo6 {
						compatible = "asr,pm813-ldo6";
						regulator-always-on;
						regulator-boot-on;
						regulator-max-microvolt = <0x325aa0>;
						regulator-min-microvolt = <0x124f80>;
					};

					regulator-ldo7 {
						compatible = "asr,pm813-ldo7";
						phandle = <0x42>;
						regulator-always-on;
						regulator-boot-on;
						regulator-max-microvolt = <0x325aa0>;
						regulator-min-microvolt = <0x124f80>;
					};

					regulator-ldo8 {
						compatible = "asr,pm813-ldo8";
						regulator-max-microvolt = <0x325aa0>;
						regulator-min-microvolt = <0x124f80>;
					};

					regulator-ldo9 {
						compatible = "asr,pm813-ldo9";
						phandle = <0x3e>;
						regulator-max-microvolt = <0x325aa0>;
						regulator-min-microvolt = <0x124f80>;
					};

					rtc {
						compatible = "asr,pm813-rtc";
						status = "disabled";
					};

					torch_led {
						compatible = "asr,pm813-torled";
						status = "disable";
					};

					vibra {
						compatible = "asr,pm813-vibra";
					};

					wdt {
						compatible = "asr,pm813-wdt";
						pm813,wdt-disabled;
						pm813,wdt_reset_soc;
					};
				};
			};

			i2c@d4020000 {
				#address-cells = <0x1>;
				#size-cells = <0x0>;
				asr,adapter-id = <0x4>;
				asr,apb_clock = <0x3197500>;
				asr,dma-disable;
				asr,i2c-clk-rate = <0x1e84800>;
				asr,i2c-lcr = <0x82c469f>;
				asr,i2c-master-code = [0e];
				asr,i2c-wcr = <0x142a>;
				clocks = <0xb 0xcc>;
				compatible = "asr,asr-i2c";
				dma-names = "rx", "tx";
				dmas = <0x23 0x16 0x1 0x23 0x15 0x1>;
				interrupts = <0x0 0x18 0x4>;
				lpm-qos = <0x7>;
				reg = <0xd4020000 0x38>;
				status = "disabled";
			};

			i2c@d4020800 {
				#address-cells = <0x1>;
				#size-cells = <0x0>;
				asr,adapter-id = <0x5>;
				asr,apb_clock = <0x3197500>;
				asr,dma-disable;
				asr,i2c-clk-rate = <0x1e84800>;
				asr,i2c-fast-mode;
				asr,i2c-lcr = <0x82c469f>;
				asr,i2c-master-code = [0e];
				asr,i2c-wcr = <0x142a>;
				clocks = <0xb 0xcd>;
				compatible = "asr,asr-i2c";
				dma-names = "rx", "tx";
				dmas = <0x23 0x18 0x1 0x23 0x17 0x1>;
				interrupts = <0x0 0x19 0x4>;
				lpm-qos = <0x7>;
				reg = <0xd4020800 0x38>;
				status = "ok";

				gcore_tp@26 {
					compatible = "gcore,touchscreen";
					gcore,irq-gpio = <0x12 0x7 0x0>;
					gcore,rst-gpio = <0x12 0x8 0x0>;
					pinctrl-0 = <0x27>;
					pinctrl-names = "default";
					reg = <0x26>;
					status = "disabled";
				};
			};

			i2c@d4021000 {
				#address-cells = <0x1>;
				#size-cells = <0x0>;
				asr,adapter-id = <0x6>;
				asr,apb_clock = <0x3197500>;
				asr,dma-disable;
				asr,i2c-clk-rate = <0x1e84800>;
				asr,i2c-fast-mode;
				asr,i2c-lcr = <0x82c469f>;
				asr,i2c-master-code = [0e];
				asr,i2c-wcr = <0x142a>;
				clocks = <0xb 0xce>;
				compatible = "asr,asr-i2c";
				dma-names = "rx", "tx";
				dmas = <0x23 0x1a 0x1 0x23 0x19 0x1>;
				interrupts = <0x0 0x1a 0x4>;
				lpm-qos = <0x7>;
				reg = <0xd4021000 0x38>;
				status = "ok";

				cst78xx@15 {
					compatible = "hynitron,cst78xx";
					irq-gpio = <0x12 0x18 0x0>;
					reg = <0x15>;
					resolution = <0x168 0x168>;
					rst-gpio = <0x12 0x19 0x0>;
					status = "disabled";
				};

				ft6x36@38 {
					compatible = "fts,ft6x36";
					irq-gpio = <0x12 0x18 0x0>;
					real-resolution = <0xf0 0xc8>;
					reg = <0x38>;
					resolution = <0xf0 0xf0>;
					rst-gpio = <0x12 0x19 0x0>;
					status = "okay";
				};
			};

			i2c@d4021800 {
				#address-cells = <0x1>;
				#size-cells = <0x0>;
				asr,adapter-id = <0x7>;
				asr,apb_clock = <0x3197500>;
				asr,dma-disable;
				asr,i2c-clk-rate = <0x1e84800>;
				asr,i2c-fast-mode;
				asr,i2c-lcr = <0x82c469f>;
				asr,i2c-master-code = [0e];
				asr,i2c-wcr = <0x142a>;
				clocks = <0xb 0xcf>;
				compatible = "asr,asr-i2c";
				dma-names = "rx", "tx";
				dmas = <0x23 0x1c 0x1 0x23 0x1b 0x1>;
				interrupts = <0x0 0x1b 0x4>;
				lpm-qos = <0x7>;
				reg = <0xd4021800 0x38>;
				status = "disabled";
			};

			i2c@d4022000 {
				#address-cells = <0x1>;
				#size-cells = <0x0>;
				asr,adapter-id = <0x8>;
				asr,apb_clock = <0x3197500>;
				asr,dma-disable;
				asr,i2c-clk-rate = <0x1e84800>;
				asr,i2c-fast-mode;
				asr,i2c-lcr = <0x82c469f>;
				asr,i2c-master-code = [0e];
				asr,i2c-wcr = <0x142a>;
				clocks = <0xb 0xd0>;
				compatible = "asr,asr-i2c";
				dma-names = "rx", "tx";
				dmas = <0x23 0x1e 0x1 0x23 0x1d 0x1>;
				interrupts = <0x0 0x1c 0x4>;
				lpm-qos = <0x7>;
				reg = <0xd4022000 0x64>;
				status = "disabled";
			};

			pdma@d4000000 {
				#dma-cells = <0x2>;
				#dma-channels = <0x10>;
				compatible = "asr,pdma-1.0";
				interrupts = <0x0 0x38 0x4>;
				lpm-qos = <0x7>;
				max-burst-size = <0x40>;
				phandle = <0x23>;
				reg = <0xd4000000 0x10000>;
				reserved-channels = <0x11>;
				status = "ok";
			};

			pinmux@d401e000 {
				#address-cells = <0x1>;
				#gpio-range-cells = <0x3>;
				#pinctrl-cells = <0x1>;
				#size-cells = <0x1>;
				compatible = "pinconf-single";
				phandle = <0x26>;
				pinctrl-0 = <0x24 0x25>;
				pinctrl-names = "default";
				pinctrl-single,function-mask = <0x7>;
				pinctrl-single,register-width = <0x20>;
				ranges;
				reg = <0xd401e000 0x400>;
				status = "ok";

				a4_spi_lcd_3line2lane {
					pinctrl-single,bias-pulldown = <0x8000 0xa000 0x8000 0xa000>;
					pinctrl-single,bias-pullup = <0xc000 0xc000 0x0 0xc000>;
					pinctrl-single,drive-strength = <0x1000 0x1800>;
					pinctrl-single,input-schmitt = <0x0 0x30>;
					pinctrl-single,input-schmitt-enable = <0x40 0x0 0x40 0x40>;
					pinctrl-single,low-power-mode = <0x0 0x388>;
					pinctrl-single,pins = <0xc 0x2 0x1c 0x2 0x2c 0x2 0x5c 0x2 0x60 0x2>;
				};

				a4_spi_lcd_4line1lane {
					pinctrl-single,bias-pulldown = <0x8000 0xa000 0x8000 0xa000>;
					pinctrl-single,bias-pullup = <0xc000 0xc000 0x0 0xc000>;
					pinctrl-single,drive-strength = <0x1000 0x1800>;
					pinctrl-single,input-schmitt = <0x0 0x30>;
					pinctrl-single,input-schmitt-enable = <0x40 0x0 0x40 0x40>;
					pinctrl-single,low-power-mode = <0x0 0x388>;
					pinctrl-single,pins = <0xc 0x2 0x1c 0x2 0x2c 0x2 0x5c 0x2 0x60 0x3>;
				};

				a4_spi_lcd_qspi {
					pinctrl-single,bias-pulldown = <0x8000 0xa000 0x8000 0xa000>;
					pinctrl-single,bias-pullup = <0xc000 0xc000 0x0 0xc000>;
					pinctrl-single,drive-strength = <0x1000 0x1800>;
					pinctrl-single,input-schmitt = <0x0 0x30>;
					pinctrl-single,input-schmitt-enable = <0x40 0x0 0x40 0x40>;
					pinctrl-single,low-power-mode = <0x0 0x388>;
					pinctrl-single,pins = <0xc 0x2 0x1c 0x2 0x2c 0x2 0x5c 0x2 0x60 0x2 0x38 0x3 0x44 0x3>;
				};

				btl_ts_pmx_func0 {
					pinctrl-single,bias-pulldown = <0x8000 0xa000 0x8000 0xa000>;
					pinctrl-single,bias-pullup = <0xc000 0xc000 0x0 0xc000>;
					pinctrl-single,drive-strength = <0x1000 0x1800>;
					pinctrl-single,input-schmitt = <0x0 0x30>;
					pinctrl-single,input-schmitt-enable = <0x40 0x0 0x40 0x40>;
					pinctrl-single,low-power-mode = <0x0 0x388>;
					pinctrl-single,pins = <0x20 0x0>;
				};

				ccic1_pmx_func1 {
					pinctrl-single,bias-pulldown = <0x0 0xa000 0x0 0xa000>;
					pinctrl-single,bias-pullup = <0x0 0xc000 0x0 0xc000>;
					pinctrl-single,drive-strength = <0x1000 0x1800>;
					pinctrl-single,input-schmitt = <0x0 0x30>;
					pinctrl-single,input-schmitt-enable = <0x40 0x0 0x40 0x40>;
					pinctrl-single,low-power-mode = <0x0 0x388>;
					pinctrl-single,pins = <0x28 0x0 0x34 0x0 0x40 0x1>;
				};

				ccic2_pmx_func1 {
					pinctrl-single,bias-pulldown = <0x0 0xa000 0x0 0xa000>;
					pinctrl-single,bias-pullup = <0x0 0xc000 0x0 0xc000>;
					pinctrl-single,drive-strength = <0x1000 0x1800>;
					pinctrl-single,input-schmitt = <0x0 0x30>;
					pinctrl-single,input-schmitt-enable = <0x40 0x0 0x40 0x40>;
					pinctrl-single,low-power-mode = <0x0 0x388>;
					pinctrl-single,pins = <0x2c 0x0 0x38 0x0 0x44 0x1>;
				};

				ccic3_pmx_func1 {
					pinctrl-single,bias-pulldown = <0x0 0xa000 0x0 0xa000>;
					pinctrl-single,bias-pullup = <0x0 0xc000 0x0 0xc000>;
					pinctrl-single,drive-strength = <0x1000 0x1800>;
					pinctrl-single,input-schmitt = <0x0 0x30>;
					pinctrl-single,input-schmitt-enable = <0x40 0x0 0x40 0x40>;
					pinctrl-single,low-power-mode = <0x0 0x388>;
					pinctrl-single,pins = <0x30 0x0 0x3c 0x0 0x48 0x1>;
				};

				evb_a0_mfp_pins_group_0 {
					phandle = <0x24>;
					pinctrl-single,bias-pulldown = <0x0 0xa000 0x0 0xa000>;
					pinctrl-single,bias-pullup = <0x0 0xc000 0x0 0xc000>;
					pinctrl-single,drive-strength = <0x1000 0x1800>;
					pinctrl-single,input-schmitt = <0x0 0x30>;
					pinctrl-single,input-schmitt-enable = <0x40 0x0 0x40 0x40>;
					pinctrl-single,low-power-mode = <0x0 0x388>;
					pinctrl-single,pins = <0x10 0x1 0x14 0x1 0x28 0x0 0x30 0x0 0x34 0x0 0x3c 0x0 0x40 0x1 0x48 0x1 0x4c 0x1 0x50 0x1 0x54 0x1 0x58 0x1 0x64 0x0 0x214 0x1 0x218 0x1 0x21c 0x0 0x220 0x2 0x224 0x0 0x228 0x2 0x22c 0x2 0x230 0x1 0x234 0x1 0x23c 0x1 0x240 0x0 0x244 0x0 0x248 0x0 0x24c 0x0 0x250 0x0 0x268 0x0 0x26c 0x0 0x270 0x0 0x274 0x0 0x278 0x2 0x27c 0x2 0x280 0x2 0x284 0x2 0x288 0x0 0x28c 0x0 0x290 0x0 0x294 0x0 0x298 0x0 0x29c 0x0 0x2a0 0x0 0x2a8 0x0 0x2ac 0x0 0x2b4 0x0 0x2c8 0x0 0x2d0 0x0 0x2e0 0x0 0x2ec 0x0 0x2f0 0x0 0x2f4 0x0 0x2f8 0x0 0x2fc 0x0 0x300 0x0 0x314 0x1 0x318 0x1 0x320 0x1 0x33c 0x1 0x340 0x1 0x344 0x1 0x348 0x1 0x350 0x1 0x354 0x0 0x358 0x0 0x35c 0x0 0x360 0x0 0x364 0x1 0x368 0x1 0x36c 0x0 0x370 0x0 0x374 0x1 0x378 0x1 0x38c 0x0 0x398 0x1 0x3a0 0x1 0x204 0x0>;
				};

				evb_a0_mfp_pins_group_1 {
					phandle = <0x25>;
					pinctrl-single,bias-pulldown = <0x8000 0x8000 0x0 0xa000>;
					pinctrl-single,bias-pullup = <0x8000 0x8000 0x0 0xc000>;
					pinctrl-single,drive-strength = <0x1000 0x1800>;
					pinctrl-single,input-schmitt = <0x0 0x30>;
					pinctrl-single,input-schmitt-enable = <0x40 0x0 0x40 0x40>;
					pinctrl-single,low-power-mode = <0x0 0x388>;
					pinctrl-single,pins = <0x8 0x0 0x18 0x2 0x254 0x0 0x2c0 0x1 0x2c4 0x1 0x2d4 0x0 0x31c 0x1 0x34c 0x0>;
				};

				evb_mfp_pins_group_0 {
					pinctrl-single,bias-pulldown = <0xa000 0xa000 0x0 0xa000>;
					pinctrl-single,bias-pullup = <0x8000 0xc000 0x8000 0xc000>;
					pinctrl-single,drive-strength = <0x1000 0x1800>;
					pinctrl-single,input-schmitt = <0x0 0x30>;
					pinctrl-single,input-schmitt-enable = <0x40 0x0 0x40 0x40>;
					pinctrl-single,low-power-mode = <0x0 0x388>;
					pinctrl-single,pins = <0x394 0x0>;
				};

				evb_mfp_pins_group_1 {
					pinctrl-single,bias-pulldown = <0x0 0xa000 0x0 0xa000>;
					pinctrl-single,bias-pullup = <0x0 0xc000 0x0 0xc000>;
					pinctrl-single,drive-strength = <0x1000 0x1800>;
					pinctrl-single,input-schmitt = <0x0 0x30>;
					pinctrl-single,input-schmitt-enable = <0x40 0x0 0x40 0x40>;
					pinctrl-single,low-power-mode = <0x0 0x388>;
					pinctrl-single,pins = <0x20 0x0 0x10 0x1 0x14 0x1 0x258 0x1 0x25c 0x1 0x5c 0x1 0x60 0x1 0x364 0x1 0x368 0x1 0x2a0 0x1 0x2a4 0x1 0x220 0x1 0x224 0x1 0x228 0x1 0x22c 0x1 0x33c 0x1 0x340 0x1 0x344 0x1 0x348 0x1 0x2ec 0x1 0x2f0 0x1 0x2f4 0x1 0x2f8 0x1 0x2fc 0x1 0x300 0x1 0x304 0x1 0x308 0x1 0x298 0x1 0x29c 0x1 0x248 0x1 0x24c 0x1 0x250 0x1 0x254 0x1 0x64 0x0 0x68 0x0 0x24 0x0 0x314 0x1 0x318 0x1 0x31c 0x1 0x320 0x1 0x28 0x0 0x2c 0x0 0x30 0x0 0x34 0x0 0x38 0x0 0x3c 0x0 0x40 0x1 0x44 0x1 0x48 0x1>;
				};

				goodix_ts_pmx_func0 {
					phandle = <0x27>;
					pinctrl-single,bias-pulldown = <0xa000 0xa000 0x0 0xa000>;
					pinctrl-single,bias-pullup = <0x8000 0xc000 0x8000 0xc000>;
					pinctrl-single,drive-strength = <0x1000 0x1800>;
					pinctrl-single,input-schmitt = <0x0 0x30>;
					pinctrl-single,input-schmitt-enable = <0x40 0x0 0x40 0x40>;
					pinctrl-single,low-power-mode = <0x0 0x388>;
					pinctrl-single,pins = <0x20 0x0 0x24 0x0>;
				};

				gpio-range {
					#pinctrl-single,gpio-range-cells = <0x3>;
				};

				gpio126_pmx_func0 {
					phandle = <0x18>;
					pinctrl-single,bias-pulldown = <0x8000 0xa000 0x8000 0xa000>;
					pinctrl-single,bias-pullup = <0xc000 0xc000 0x0 0xc000>;
					pinctrl-single,drive-strength = <0x1000 0x1800>;
					pinctrl-single,input-schmitt = <0x0 0x30>;
					pinctrl-single,input-schmitt-enable = <0x40 0x0 0x40 0x40>;
					pinctrl-single,low-power-mode = <0x288 0x388>;
					pinctrl-single,pins = <0x39c 0x0>;
				};

				gpio126_pmx_func2 {
					phandle = <0x1d>;
					pinctrl-single,bias-pulldown = <0x0 0xa000 0x0 0xa000>;
					pinctrl-single,bias-pullup = <0x0 0xc000 0x0 0xc000>;
					pinctrl-single,drive-strength = <0x1000 0x1800>;
					pinctrl-single,input-schmitt = <0x0 0x30>;
					pinctrl-single,input-schmitt-enable = <0x40 0x0 0x40 0x40>;
					pinctrl-single,low-power-mode = <0x0 0x388>;
					pinctrl-single,pins = <0x39c 0x2>;
				};

				gpio51_pmx_func0 {
					pinctrl-single,bias-pulldown = <0x8000 0xa000 0x8000 0xa000>;
					pinctrl-single,bias-pullup = <0xc000 0xc000 0x0 0xc000>;
					pinctrl-single,drive-strength = <0x1000 0x1800>;
					pinctrl-single,input-schmitt = <0x0 0x30>;
					pinctrl-single,input-schmitt-enable = <0x40 0x0 0x40 0x40>;
					pinctrl-single,low-power-mode = <0x288 0x388>;
					pinctrl-single,pins = <0x270 0x0>;
				};

				gpio51_pmx_func2 {
					pinctrl-single,bias-pulldown = <0x0 0xa000 0x0 0xa000>;
					pinctrl-single,bias-pullup = <0x0 0xc000 0x0 0xc000>;
					pinctrl-single,drive-strength = <0x1000 0x1800>;
					pinctrl-single,input-schmitt = <0x0 0x30>;
					pinctrl-single,input-schmitt-enable = <0x40 0x0 0x40 0x40>;
					pinctrl-single,low-power-mode = <0x0 0x388>;
					pinctrl-single,pins = <0x270 0x2>;
				};

				mipi_te_func {
					pinctrl-single,bias-pulldown = <0x0 0xa000 0x0 0xa000>;
					pinctrl-single,bias-pullup = <0x0 0xc000 0x0 0xc000>;
					pinctrl-single,drive-strength = <0x1000 0x1800>;
					pinctrl-single,input-schmitt = <0x0 0x30>;
					pinctrl-single,input-schmitt-enable = <0x40 0x0 0x40 0x40>;
					pinctrl-single,low-power-mode = <0x0 0x388>;
					pinctrl-single,pins = <0x4 0x1>;
				};

				mipi_te_gpio {
					pinctrl-single,bias-pulldown = <0x0 0xa000 0x0 0xa000>;
					pinctrl-single,bias-pullup = <0x0 0xc000 0x0 0xc000>;
					pinctrl-single,drive-strength = <0x1000 0x1800>;
					pinctrl-single,input-schmitt = <0x0 0x30>;
					pinctrl-single,input-schmitt-enable = <0x40 0x0 0x40 0x40>;
					pinctrl-single,low-power-mode = <0x0 0x388>;
					pinctrl-single,pins = <0x4 0x0>;
				};

				pm833_pin_func0 {
					pinctrl-single,bias-pulldown = <0x8000 0xa000 0x8000 0xa000>;
					pinctrl-single,bias-pullup = <0xc000 0xc000 0x0 0xc000>;
					pinctrl-single,drive-strength = <0x1000 0x1800>;
					pinctrl-single,input-schmitt = <0x0 0x30>;
					pinctrl-single,input-schmitt-enable = <0x40 0x0 0x40 0x40>;
					pinctrl-single,low-power-mode = <0x0 0x388>;
					pinctrl-single,pins = <0x2d8 0x0>;
				};

				sdcard_clk_pmx_func0 {
					phandle = <0x19>;
					pinctrl-single,bias-pulldown = <0xa000 0xa000 0x0 0xa000>;
					pinctrl-single,bias-pullup = <0x8000 0xc000 0x8000 0xc000>;
					pinctrl-single,drive-strength = <0x800 0x1800>;
					pinctrl-single,input-schmitt = <0x0 0x30>;
					pinctrl-single,input-schmitt-enable = <0x40 0x0 0x40 0x40>;
					pinctrl-single,low-power-mode = <0x208 0x388>;
					pinctrl-single,pins = <0x1cc 0x0>;
				};

				sdcard_clk_pmx_func0_fast {
					phandle = <0x1b>;
					pinctrl-single,bias-pulldown = <0xa000 0xa000 0x0 0xa000>;
					pinctrl-single,bias-pullup = <0x8000 0xc000 0x8000 0xc000>;
					pinctrl-single,drive-strength = <0x1800 0x1800>;
					pinctrl-single,input-schmitt = <0x0 0x30>;
					pinctrl-single,input-schmitt-enable = <0x40 0x0 0x40 0x40>;
					pinctrl-single,low-power-mode = <0x208 0x388>;
					pinctrl-single,pins = <0x1cc 0x0>;
				};

				sdcard_pmx_func0 {
					phandle = <0x17>;
					pinctrl-single,bias-pulldown = <0x8000 0xa000 0x8000 0xa000>;
					pinctrl-single,bias-pullup = <0xc000 0xc000 0x0 0xc000>;
					pinctrl-single,drive-strength = <0x800 0x1800>;
					pinctrl-single,input-schmitt = <0x0 0x30>;
					pinctrl-single,input-schmitt-enable = <0x40 0x0 0x40 0x40>;
					pinctrl-single,low-power-mode = <0x0 0x388>;
					pinctrl-single,pins = <0x1b8 0x0 0x1bc 0x0 0x1c0 0x0 0x1c4 0x0 0x1c8 0x0>;
				};

				sdcard_pmx_func0_fast {
					phandle = <0x1a>;
					pinctrl-single,bias-pulldown = <0x8000 0xa000 0x8000 0xa000>;
					pinctrl-single,bias-pullup = <0xc000 0xc000 0x0 0xc000>;
					pinctrl-single,drive-strength = <0x1800 0x1800>;
					pinctrl-single,input-schmitt = <0x0 0x30>;
					pinctrl-single,input-schmitt-enable = <0x40 0x0 0x40 0x40>;
					pinctrl-single,low-power-mode = <0x0 0x388>;
					pinctrl-single,pins = <0x1b8 0x0 0x1bc 0x0 0x1c0 0x0 0x1c4 0x0 0x1c8 0x0>;
				};

				sdcard_pmx_func2 {
					phandle = <0x1c>;
					pinctrl-single,bias-pulldown = <0x0 0xa000 0x0 0xa000>;
					pinctrl-single,bias-pullup = <0x0 0xc000 0x0 0xc000>;
					pinctrl-single,drive-strength = <0x1000 0x1800>;
					pinctrl-single,input-schmitt = <0x0 0x30>;
					pinctrl-single,input-schmitt-enable = <0x40 0x0 0x40 0x40>;
					pinctrl-single,low-power-mode = <0x0 0x388>;
					pinctrl-single,pins = <0x1b8 0x2 0x1bc 0x2 0x1c0 0x2 0x1c4 0x2 0x1c8 0x2 0x1cc 0x2>;
				};

				sdio_clk_pmx_func1 {
					phandle = <0x1f>;
					pinctrl-single,bias-pulldown = <0x0 0xa000 0x0 0xa000>;
					pinctrl-single,bias-pullup = <0x0 0xc000 0x0 0xc000>;
					pinctrl-single,drive-strength = <0x1000 0x1800>;
					pinctrl-single,input-schmitt = <0x0 0x30>;
					pinctrl-single,input-schmitt-enable = <0x40 0x0 0x40 0x40>;
					pinctrl-single,low-power-mode = <0x208 0x388>;
					pinctrl-single,pins = <0x338 0x1>;
				};

				sdio_clk_pmx_func1_fast {
					phandle = <0x21>;
					pinctrl-single,bias-pulldown = <0x0 0xa000 0x0 0xa000>;
					pinctrl-single,bias-pullup = <0x0 0xc000 0x0 0xc000>;
					pinctrl-single,drive-strength = <0x1800 0x1800>;
					pinctrl-single,input-schmitt = <0x0 0x30>;
					pinctrl-single,input-schmitt-enable = <0x40 0x0 0x40 0x40>;
					pinctrl-single,low-power-mode = <0x208 0x388>;
					pinctrl-single,pins = <0x338 0x1>;
				};

				sdio_pmx_func1 {
					phandle = <0x1e>;
					pinctrl-single,bias-pulldown = <0x0 0xa000 0x0 0xa000>;
					pinctrl-single,bias-pullup = <0x0 0xc000 0x0 0xc000>;
					pinctrl-single,drive-strength = <0x1000 0x1800>;
					pinctrl-single,input-schmitt = <0x0 0x30>;
					pinctrl-single,input-schmitt-enable = <0x40 0x0 0x40 0x40>;
					pinctrl-single,low-power-mode = <0x0 0x388>;
					pinctrl-single,pins = <0x324 0x1 0x328 0x1 0x32c 0x1 0x330 0x1 0x334 0x1>;
				};

				sdio_pmx_func1_fast {
					phandle = <0x20>;
					pinctrl-single,bias-pulldown = <0x0 0xa000 0x0 0xa000>;
					pinctrl-single,bias-pullup = <0x0 0xc000 0x0 0xc000>;
					pinctrl-single,drive-strength = <0x1800 0x1800>;
					pinctrl-single,input-schmitt = <0x0 0x30>;
					pinctrl-single,input-schmitt-enable = <0x40 0x0 0x40 0x40>;
					pinctrl-single,low-power-mode = <0x0 0x388>;
					pinctrl-single,pins = <0x324 0x1 0x328 0x1 0x32c 0x1 0x330 0x1 0x334 0x1>;
				};

				sh_i2c_pmx_func4 {
					phandle = <0x45>;
					pinctrl-single,bias-pulldown = <0x0 0xa000 0x0 0xa000>;
					pinctrl-single,bias-pullup = <0x0 0xc000 0x0 0xc000>;
					pinctrl-single,drive-strength = <0x1000 0x1800>;
					pinctrl-single,input-schmitt = <0x0 0x30>;
					pinctrl-single,input-schmitt-enable = <0x40 0x0 0x40 0x40>;
					pinctrl-single,low-power-mode = <0x0 0x388>;
					pinctrl-single,pins = <0x2b8 0x1 0x2bc 0x1>;
				};

				sim_card_pins_group_0 {
					phandle = <0x46>;
					pinctrl-single,bias-pulldown = <0x8000 0xa000 0x8000 0xa000>;
					pinctrl-single,bias-pullup = <0xc000 0xc000 0x0 0xc000>;
					pinctrl-single,drive-strength = <0x1000 0x1800>;
					pinctrl-single,input-schmitt = <0x0 0x30>;
					pinctrl-single,input-schmitt-enable = <0x40 0x0 0x40 0x40>;
					pinctrl-single,low-power-mode = <0x0 0x388>;
					pinctrl-single,pins = <0x2e4 0x0 0x2e8 0x0>;
				};

				spi_lcd_3line2lane {
					phandle = <0x35>;
					pinctrl-single,bias-pulldown = <0x8000 0xa000 0x8000 0xa000>;
					pinctrl-single,bias-pullup = <0xc000 0xc000 0x0 0xc000>;
					pinctrl-single,drive-strength = <0x1000 0x1800>;
					pinctrl-single,input-schmitt = <0x0 0x30>;
					pinctrl-single,input-schmitt-enable = <0x40 0x0 0x40 0x40>;
					pinctrl-single,low-power-mode = <0x0 0x388>;
					pinctrl-single,pins = <0xc 0x2 0x1c 0x2 0x2c 0x2 0x5c 0x2 0x60 0x2>;
				};

				spi_lcd_4line1lane {
					phandle = <0x36>;
					pinctrl-single,bias-pulldown = <0x8000 0xa000 0x8000 0xa000>;
					pinctrl-single,bias-pullup = <0xc000 0xc000 0x0 0xc000>;
					pinctrl-single,drive-strength = <0x1000 0x1800>;
					pinctrl-single,input-schmitt = <0x0 0x30>;
					pinctrl-single,input-schmitt-enable = <0x40 0x0 0x40 0x40>;
					pinctrl-single,low-power-mode = <0x0 0x388>;
					pinctrl-single,pins = <0xc 0x2 0x1c 0x2 0x2c 0x2 0x5c 0x2 0x60 0x3>;
				};

				spi_lcd_qspi {
					phandle = <0x34>;
					pinctrl-single,bias-pulldown = <0x8000 0xa000 0x8000 0xa000>;
					pinctrl-single,bias-pullup = <0xc000 0xc000 0x0 0xc000>;
					pinctrl-single,drive-strength = <0x1000 0x1800>;
					pinctrl-single,input-schmitt = <0x0 0x30>;
					pinctrl-single,input-schmitt-enable = <0x40 0x0 0x40 0x40>;
					pinctrl-single,low-power-mode = <0x0 0x388>;
					pinctrl-single,pins = <0xc 0x2 0x1c 0x2 0x2c 0x2 0x5c 0x2 0x60 0x2 0x38 0x3 0x44 0x3>;
				};

				ssp0_pmx_func0 {
					pinctrl-single,bias-pulldown = <0xa000 0xa000 0x0 0xa000>;
					pinctrl-single,bias-pullup = <0x8000 0xc000 0x8000 0xc000>;
					pinctrl-single,drive-strength = <0x1000 0x1800>;
					pinctrl-single,input-schmitt = <0x0 0x30>;
					pinctrl-single,input-schmitt-enable = <0x40 0x0 0x40 0x40>;
					pinctrl-single,low-power-mode = <0x0 0x388>;
					pinctrl-single,pins = <0x37c 0x1 0x384 0x1 0x388 0x1>;
				};

				ssp0_pmx_func1 {
					pinctrl-single,bias-pulldown = <0x8000 0xa000 0x8000 0xa000>;
					pinctrl-single,bias-pullup = <0xc000 0xc000 0x0 0xc000>;
					pinctrl-single,drive-strength = <0x1000 0x1800>;
					pinctrl-single,input-schmitt = <0x0 0x30>;
					pinctrl-single,input-schmitt-enable = <0x40 0x0 0x40 0x40>;
					pinctrl-single,low-power-mode = <0x0 0x388>;
					pinctrl-single,pins = <0x380 0x1>;
				};

				twsi0_pmx_func0 {
					pinctrl-single,bias-pulldown = <0x0 0xa000 0x0 0xa000>;
					pinctrl-single,bias-pullup = <0x0 0xc000 0x0 0xc000>;
					pinctrl-single,drive-strength = <0x1000 0x1800>;
					pinctrl-single,input-schmitt = <0x0 0x30>;
					pinctrl-single,input-schmitt-enable = <0x40 0x0 0x40 0x40>;
					pinctrl-single,low-power-mode = <0x0 0x388>;
					pinctrl-single,pins = <0x4c 0x0 0x50 0x0>;
				};

				twsi0_pmx_func1 {
					pinctrl-single,bias-pulldown = <0x0 0xa000 0x0 0xa000>;
					pinctrl-single,bias-pullup = <0x0 0xc000 0x0 0xc000>;
					pinctrl-single,drive-strength = <0x1000 0x1800>;
					pinctrl-single,input-schmitt = <0x0 0x30>;
					pinctrl-single,input-schmitt-enable = <0x40 0x0 0x40 0x40>;
					pinctrl-single,low-power-mode = <0x0 0x388>;
					pinctrl-single,pins = <0x4c 0x1 0x50 0x1>;
				};

				twsi0_pmx_func2 {
					pinctrl-single,bias-pulldown = <0x0 0xa000 0x0 0xa000>;
					pinctrl-single,bias-pullup = <0x0 0xc000 0x0 0xc000>;
					pinctrl-single,drive-strength = <0x1000 0x1800>;
					pinctrl-single,input-schmitt = <0x0 0x30>;
					pinctrl-single,input-schmitt-enable = <0x40 0x0 0x40 0x40>;
					pinctrl-single,low-power-mode = <0x0 0x388>;
					pinctrl-single,pins = <0x4c 0x2 0x50 0x2>;
				};

				twsi1_pmx_func0 {
					pinctrl-single,bias-pulldown = <0x0 0xa000 0x0 0xa000>;
					pinctrl-single,bias-pullup = <0x0 0xc000 0x0 0xc000>;
					pinctrl-single,drive-strength = <0x1000 0x1800>;
					pinctrl-single,input-schmitt = <0x0 0x30>;
					pinctrl-single,input-schmitt-enable = <0x40 0x0 0x40 0x40>;
					pinctrl-single,low-power-mode = <0x0 0x388>;
					pinctrl-single,pins = <0x54 0x0 0x58 0x0>;
				};

				twsi1_pmx_func1 {
					pinctrl-single,bias-pulldown = <0x0 0xa000 0x0 0xa000>;
					pinctrl-single,bias-pullup = <0x0 0xc000 0x0 0xc000>;
					pinctrl-single,drive-strength = <0x1000 0x1800>;
					pinctrl-single,input-schmitt = <0x0 0x30>;
					pinctrl-single,input-schmitt-enable = <0x40 0x0 0x40 0x40>;
					pinctrl-single,low-power-mode = <0x0 0x388>;
					pinctrl-single,pins = <0x54 0x1 0x58 0x1>;
				};

				twsi1_pmx_func2 {
					pinctrl-single,bias-pulldown = <0x0 0xa000 0x0 0xa000>;
					pinctrl-single,bias-pullup = <0x0 0xc000 0x0 0xc000>;
					pinctrl-single,drive-strength = <0x1000 0x1800>;
					pinctrl-single,input-schmitt = <0x0 0x30>;
					pinctrl-single,input-schmitt-enable = <0x40 0x0 0x40 0x40>;
					pinctrl-single,low-power-mode = <0x0 0x388>;
					pinctrl-single,pins = <0x54 0x2 0x58 0x2>;
				};

				twsi4_pmx_func1 {
					pinctrl-single,bias-pulldown = <0x0 0xa000 0x0 0xa000>;
					pinctrl-single,bias-pullup = <0x0 0xc000 0x0 0xc000>;
					pinctrl-single,drive-strength = <0x1000 0x1800>;
					pinctrl-single,input-schmitt = <0x0 0x30>;
					pinctrl-single,input-schmitt-enable = <0x40 0x0 0x40 0x40>;
					pinctrl-single,low-power-mode = <0x0 0x388>;
					pinctrl-single,pins = <0x230 0x1 0x234 0x1>;
				};

				twsi8_pmx_func1 {
					pinctrl-single,bias-pulldown = <0x0 0xa000 0x0 0xa000>;
					pinctrl-single,bias-pullup = <0x0 0xc000 0x0 0xc000>;
					pinctrl-single,drive-strength = <0x1000 0x1800>;
					pinctrl-single,input-schmitt = <0x0 0x30>;
					pinctrl-single,input-schmitt-enable = <0x40 0x0 0x40 0x40>;
					pinctrl-single,low-power-mode = <0x0 0x388>;
					pinctrl-single,pins = <0x260 0x1 0x264 0x1>;
				};

				uart2_pmx_func1 {
					pinctrl-single,bias-pulldown = <0x0 0xa000 0x0 0xa000>;
					pinctrl-single,bias-pullup = <0x0 0xc000 0x0 0xc000>;
					pinctrl-single,drive-strength = <0x1000 0x1800>;
					pinctrl-single,input-schmitt = <0x0 0x30>;
					pinctrl-single,input-schmitt-enable = <0x40 0x0 0x40 0x40>;
					pinctrl-single,low-power-mode = <0x0 0x388>;
					pinctrl-single,pins = <0x384 0x2 0x388 0x2>;
				};

				uart2_pmx_func2 {
					pinctrl-single,bias-pulldown = <0xa000 0xa000 0x0 0xa000>;
					pinctrl-single,bias-pullup = <0x8000 0xc000 0x8000 0xc000>;
					pinctrl-single,drive-strength = <0x1000 0x1800>;
					pinctrl-single,input-schmitt = <0x0 0x30>;
					pinctrl-single,input-schmitt-enable = <0x40 0x0 0x40 0x40>;
					pinctrl-single,low-power-mode = <0x0 0x388>;
					pinctrl-single,pins = <0x37c 0x2 0x380 0x2>;
				};

				watch_a6_mfp_pins_group {
					pinctrl-single,bias-pulldown = <0x0 0xa000 0x0 0xa000>;
					pinctrl-single,bias-pullup = <0x0 0xc000 0x0 0xc000>;
					pinctrl-single,drive-strength = <0x1000 0x1800>;
					pinctrl-single,input-schmitt = <0x0 0x30>;
					pinctrl-single,input-schmitt-enable = <0x40 0x0 0x40 0x40>;
					pinctrl-single,low-power-mode = <0x0 0x388>;
					pinctrl-single,pins = <0x68 0x0 0x20c 0x0 0x210 0x0 0x2cc 0x0>;
				};
			};

			pwm@d401a000 {
				#pwm-cells = <0x2>;
				clocks = <0xb 0xd6>;
				compatible = "asr,asr-pwm";
				reg = <0xd401a000 0x10>;
				status = "disabled";
			};

			pwm@d401a400 {
				#pwm-cells = <0x2>;
				clocks = <0xb 0xd7>;
				compatible = "asr,asr-pwm";
				phandle = <0x3f>;
				reg = <0xd401a400 0x10>;
				status = "okay";
			};

			pwm@d401a800 {
				#pwm-cells = <0x2>;
				clocks = <0xb 0xd9>;
				compatible = "asr,asr-pwm";
				reg = <0xd401a800 0x10>;
				status = "disabled";
			};

			pwm@d401ac00 {
				#pwm-cells = <0x2>;
				clocks = <0xb 0xda>;
				compatible = "asr,asr-pwm";
				reg = <0xd401ac00 0x10>;
				status = "disabled";
			};

			rtc@d4010000 {
				clocks = <0xb 0xd4>;
				compatible = "mrvl,mmp-rtc";
				interrupt-names = "rtc 1Hz", "rtc alarm";
				interrupts = <0x0 0x5 0x4 0x0 0x6 0x4>;
				reg = <0xd4010000 0x100>;
				status = "okay";
			};

			seh@d40b0300 {
				compatible = "asr,seh";
				interrupt-names = "CP_TIMER3";
				interrupts = <0x0 0x0 0x4>;
				reg = <0xd40b0300 0x4>;
				status = "okay";
				watchdog-type = <0x2>;
			};

			spi@d401b000 {
				#address-cells = <0x1>;
				#size-cells = <0x1>;
				asr,ssp-clock-rate = <0x18cba80>;
				asr,ssp-disable-dma;
				asr,ssp-enhancement;
				asr,ssp-id = <0x0>;
				asr,ssp-lpm-qos = <0x7>;
				clocks = <0xb 0xe1>;
				compatible = "asr,asr-spi";
				cs-gpios = <0x12 0x20 0x0>;
				dma-names = "rx", "tx";
				dmas = <0x23 0x9 0x0 0x23 0xa 0x0>;
				interrupts = <0x0 0x23 0x4>;
				reg = <0xd401b000 0x30>;
				status = "ok";

				spitp@0 {
					compatible = "jadard-spi";
					gpios = <0x12 0x7 0x0 0x12 0x8 0x0>;
					jadard,int-is-edge = <0x1>;
					jadard,irq-gpio = <0x12 0x7 0x0>;
					jadard,panel-coords = <0x0 0x2d0 0x0 0x640>;
					jadard,panel-max-points = <0xa>;
					jadard,panel-sense-nums = <0x12 0x20>;
					jadard,rst-gpio = <0x12 0x8 0x0>;
					lcm-resolution = <0x2d0 0x640>;
					reg = <0x0 0x0>;
					spi-max-frequency = <0xc65d40>;
					status = "ok";
					tpd-cfg-version = "config17";
					tpd-filter-custom-prameters = <0x0 0x0 0x0 0x0 0x0 0x0 0x0 0x0 0x0 0x0 0x0 0x0>;
					tpd-filter-custom-speed = <0x0 0x0 0x0>;
					tpd-filter-enable = <0x1>;
					tpd-filter-pixel-density = <0x92>;
					tpd-key-dim-local = <0x28 0x3d4 0x28 0x28 0x78 0x3d4 0x28 0x28 0xc8 0x3d4 0x28 0x28 0x0 0x0 0x0 0x0>;
					tpd-key-local = <0x8b 0xac 0x9e 0x0>;
					tpd-key-num = <0x3>;
					tpd-max-touch-num = <0xa>;
					tpd-resolution = <0x2d0 0x640>;
					use-tpd-button = <0x0>;
				};
			};

			spi@d401c000 {
				#address-cells = <0x1>;
				#size-cells = <0x1>;
				asr,ssp-clock-rate = <0x632ea0>;
				asr,ssp-enhancement;
				asr,ssp-id = <0x2>;
				asr,ssp-lpm-qos = <0x7>;
				clocks = <0xb 0xe2>;
				compatible = "asr,asr-spi";
				dma-names = "rx", "tx";
				dmas = <0x23 0xb 0x0 0x23 0xc 0x0>;
				interrupts = <0x0 0x24 0x4>;
				reg = <0xd401c000 0x30>;
				status = "disabled";
			};

			sulog@d40b0100 {
				clocks = <0xb 0x110>;
				compatible = "asr,sulog";
				interrupts = <0x0 0x1f 0x4>;
				reg = <0xd40b0100 0x1c>;
				status = "ok";
			};

			swjtag@d4013100 {
				clock-names = "swjtag_clk";
				clocks = <0xb 0xdf>;
				compatible = "asr,sw-jtag";
				reg = <0xd4013100 0x10>;
				status = "ok";
			};

			thermal@d4023800 {
				#thermal-sensor-cells = <0x1>;
				clock-names = "thermal_core";
				clocks = <0xb 0xde>;
				compatible = "asr,asr-thermal";
				emergent_reboot_threshold = <0x6e>;
				hot_trip_temperature = <0x157c0>;
				interrupt-names = "thermal_irq";
				interrupts = <0x0 0x28 0x4>;
				phandle = <0x37>;
				reg = <0xd4023800 0xac>;
				status = "ok";
				temperature_offset = <0x116>;
				tsensor_en_irq = <0x1 0x1 0x1 0x1 0x1 0x0>;
				tsensor_map = <0x0 0x1 0x2 0x3 0x4 0xa>;
				tsensor_names = "local", "top", "gpu", "cpu_cluster", "cpu_core", "max";
				tsensor_num = <0x6>;
			};

			timer@d4014000 {
				asr,32k-source-id = <0x1>;
				asr,timer-apb-frequency = <0x3197500>;
				asr,timer-fastclk-frequency = <0x319750>;
				asr,timer-frequency = <0x8012>;
				asr,timer-id = <0x0>;
				clocks = <0xb 0xe3>;
				compatible = "asr,soc-timer";
				reg = <0xd4014000 0xc8>;
				status = "ok";

				counter0 {
					asr,timer-broadcast;
					asr,timer-counter-id = <0x0>;
					compatible = "asr,timer-match";
					interrupts = <0x0 0x7 0x4>;
					status = "ok";
				};
			};

			timer@d4016000 {
				asr,timer-apb-frequency = <0x3197500>;
				asr,timer-fastclk-frequency = <0x319750>;
				asr,timer-frequency = <0x8012>;
				asr,timer-id = <0x0>;
				clocks = <0xb 0xe4>;
				compatible = "asr,soc-timer1";
				reg = <0xd4016000 0xc8>;
				status = "disabled";

				counter0 {
					asr,timer-counter-id = <0x0>;
					compatible = "asr,timer-match";
					interrupts = <0x0 0xa 0x4>;
					status = "disabled";
				};
			};

			timerclk@d5001000 {
				apbc-base = <0xd4015000>;
				compatible = "asr,timer-clk";
				counter = <0x64>;
				reg = <0xd5001000 0x24>;
				status = "ok";
			};

			uart@d4017000 {
				break-abnormal;
				clock-frequency = <0xc65d40>;
				clocks = <0xb 0xdb>;
				compatible = "asr,uart";
				dma-names = "rx", "tx";
				dmas = <0x23 0x3 0x1 0x23 0x4 0x1>;
				edge-wakeup-pin = <0x36>;
				interrupts = <0x0 0x20 0x4>;
				lpm-qos = <0x7>;
				reg = <0xd4017000 0x1000>;
				status = "ok";
			};

			uart@d4017800 {
				break-abnormal;
				clock-frequency = <0xc65d40>;
				clocks = <0xb 0xdd>;
				compatible = "asr,uart";
				dma-names = "rx", "tx";
				dmas = <0x23 0x13 0x1 0x23 0x14 0x1>;
				interrupts = <0x0 0x22 0x4>;
				lpm-qos = <0x7>;
				reg = <0xd4017800 0x1000>;
				status = "ok";
			};

			uart@d4018000 {
				bluetooth-uart;
				break-abnormal;
				clock-frequency = <0xc65d40>;
				clocks = <0xb 0xdc>;
				compatible = "asr,uart";
				device-control-rts;
				dma-names = "rx", "tx";
				dmas = <0x23 0x5 0x1 0x23 0x6 0x1>;
				interrupts = <0x0 0x21 0x4>;
				lpm-qos = <0x7>;
				reg = <0xd4018000 0x1000>;
				status = "ok";
			};

			uart@d4024000 {
				break-abnormal;
				clock-frequency = <0xc65d40>;
				clocks = <0xb 0x121>;
				compatible = "asr,uart";
				dma-names = "rx", "tx";
				dmas = <0x23 0x1f 0x1 0x23 0x20 0x1>;
				interrupts = <0x0 0x33 0x4>;
				lpm-qos = <0x7>;
				reg = <0xd4024000 0x1000>;
				status = "ok";
			};

			watchdog@d4080000 {
				asr,wdt-enable-restart-handler;
				clocks = <0xb 0x119>;
				compatible = "asr,soc-wdt-v0";
				interrupts = <0x0 0x13 0x4>;
				reg = <0xd4080000 0xff 0xd4050000 0x1024>;
				status = "okay";
			};
		};

		asr_crypto_engine@c0400000 {
			asr-crypto-engine-0 = <0xc0400000 0x4000>;
			compatible = "asr,crypto_engine";
			interrupts = <0x0 0x61 0x4>;
			num-engines = <0x1>;
			status = "okay";
		};

		asriommu@c0100b00 {
			#iommu-cells = <0x1>;
			clock-names = "aclk", "pclk";
			clocks = <0xb 0xf2 0xb 0x114>;
			compatible = "asr,iommu";
			interrupt-names = "v2d_iommu";
			interrupts = <0x0 0x46 0x4>;
			page-size = <0x4>;
			phandle = <0x16>;
			reg = <0x0 0xc0100b00 0x0 0x500>;
			reg-names = "v2d";
			status = "okay";
		};

		axi@d4200000 {
			#address-cells = <0x1>;
			#size-cells = <0x1>;
			compatible = "asr,axi-bus", "simple-bus";
			ranges = <0x0 0x0 0x0 0xffffffff>;
			reg = <0x0 0xd4200000 0x0 0x200000>;

			acs_mon@d4282c00 {
				compatible = "asr,asr-acs-mon";
				interrupts = <0x0 0x6b 0x4>;
				reg = <0xd4282c00 0x3d0>;
			};

			debug@d4282c00 {
				compatible = "asr,dove-axi-timeout";
				detection_modes = <0x1>;
				interrupts = <0x0 0x5c 0x4>;
				reg = <0xd4282c00 0x2d0>;
			};

			sdh@d4280000 {
				asr,aib_mmc1_io_reg = <0xd401e81c>;
				asr,apbc_asfar_reg = <0xd4015050>;
				asr,apbc_assar_reg = <0xd4015054>;
				asr,rx_dline_reg = <0x0>;
				asr,rx_tuning_limit = <0x32>;
				asr,sdh-freq = <0xc350000>;
				asr,sdh-host-caps-disable = <0x30000>;
				asr,sdh-quirks = <0x19000>;
				asr,sdh-quirks2 = <0x18000008>;
				asr,tx_delaycode = <0x32>;
				asr,tx_dline_reg = <0x0>;
				bus-width = <0x4>;
				cd-gpios = <0x12 0x7e 0x0>;
				cd-inverted;
				clock-names = "sdh-io", "sdh-core";
				clocks = <0xb 0xe8 0xb 0xe7>;
				compatible = "asr,sdh-mmc";
				interrupts = <0x0 0x53 0x4>;
				lpm-qos = <0x7>;
				no-mmc;
				no-sdio;
				pinctrl-0 = <0x17 0x18 0x19>;
				pinctrl-1 = <0x1a 0x18 0x1b>;
				pinctrl-2 = <0x1c 0x1d>;
				pinctrl-names = "default", "fast", "jtag";
				reg = <0xd4280000 0x200>;
				status = "disabled";
			};

			sdh@d4280800 {
				asr,rx_dline_reg = <0x1>;
				asr,sdh-freq = <0xc350000>;
				asr,sdh-host-caps-disable = <0xc0020>;
				asr,sdh-quirks = <0x9000>;
				asr,sdh-quirks2 = <0x10000008>;
				bus-width = <0x4>;
				clock-names = "sdh-io", "sdh-core";
				clocks = <0xb 0xe9 0xb 0xe7>;
				compatible = "asr,sdh-mmc";
				interrupts = <0x0 0x54 0x4>;
				keep-power-in-suspend;
				lpm-qos = <0x7>;
				no-mmc;
				no-sd;
				non-removable;
				pinctrl-0 = <0x1e 0x1f>;
				pinctrl-1 = <0x20 0x21>;
				pinctrl-names = "default", "fast";
				reg = <0xd4280800 0x200>;
				status = "ok";
			};

			sdh@d4281000 {
				asr,phy_driver_sel = <0x7>;
				asr,sdh-freq = <0x165a0bc0>;
				asr,sdh-quirks = <0x9000>;
				asr,sdh-quirks2 = <0x8>;
				bus-width = <0x8>;
				clock-names = "sdh-io", "sdh-core";
				clocks = <0xb 0xea 0xb 0xe7>;
				compatible = "asr,sdh-mmc";
				fixed-emmc-driver-type = <0x1>;
				interrupts = <0x0 0x55 0x4>;
				lpm-qos = <0x7>;
				mmc-hs400-1_8v;
				mmc-hs400-enhanced-strobe;
				no-sd;
				no-sdio;
				non-removable;
				reg = <0xd4281000 0x200>;
				status = "ok";
			};
		};

		cam_sensor@0 {
			af_2v8-supply = <0x3b>;
			avdd_2v8-supply = <0x3c>;
			cell-index = <0x0>;
			clock-names = "cam_mclk0";
			clocks = <0xb 0x106>;
			compatible = "asr,cam-sensor";
			dovdd_1v8-supply = <0x3d>;
			dphy-index = <0x0>;
			dvdd_1v2-supply = <0x3e>;
			reset-gpios = <0x12 0x9 0x0>;
			status = "okay";
			twsi-index = <0x0>;
		};

		cam_sensor@1 {
			cell-index = <0x1>;
			clock-names = "cam_mclk1";
			clocks = <0xb 0x107>;
			compatible = "asr,cam-sensor";
			dphy-index = <0x2>;
			status = "okay";
			twsi-index = <0x1>;
		};

		cam_sensor@2 {
			avdd_2v8-supply = <0x3c>;
			cell-index = <0x2>;
			clock-names = "cam_mclk2";
			clocks = <0xb 0x108>;
			compatible = "asr,cam-sensor";
			dovdd_1v8-supply = <0x3d>;
			dphy-index = <0x2>;
			dvdd_1v2-supply = <0x3e>;
			reset-gpios = <0x12 0xb 0x0>;
			status = "okay";
			twsi-index = <0x1>;
		};

		ccic@d4206000 {
			asr,csiphy = <0x33>;
			cell-index = <0x2>;
			clock-names = "csi_func", "ccic_func", "isp_ahb", "isp_axi";
			clocks = <0xb 0x105 0xb 0x100 0xb 0x101 0xb 0xfe>;
			compatible = "asr,mars11ccic";
			interrupt-names = "ipe-irq";
			interrupts = <0x0 0x43 0x4>;
			reg = <0x0 0xd4206000 0x0 0x3ff>;
			reg-names = "ccic-regs";
			status = "okay";
		};

		ccic@d420a000 {
			asr,csiphy = <0x32>;
			cell-index = <0x0>;
			clock-names = "csi_func", "ccic_func", "isp_ahb", "isp_axi";
			clocks = <0xb 0x105 0xb 0x100 0xb 0x101 0xb 0xfe>;
			compatible = "asr,mars11ccic";
			interrupt-names = "ipe-irq";
			interrupts = <0x0 0x41 0x4>;
			reg = <0x0 0xd420a000 0x0 0x3ff>;
			reg-names = "ccic-regs";
			status = "okay";
		};

		ccic@d420a800 {
			asr,csiphy = <0x33>;
			cell-index = <0x1>;
			clock-names = "csi_func", "ccic_func", "isp_ahb", "isp_axi";
			clocks = <0xb 0x105 0xb 0x100 0xb 0x101 0xb 0xfe>;
			compatible = "asr,mars11ccic";
			interrupt-names = "ipe-irq";
			interrupts = <0x0 0x42 0x4>;
			reg = <0x0 0xd420a800 0x0 0x3ff>;
			reg-names = "ccic-regs";
			status = "okay";
		};

		cpp@C02f0000 {
			clock-names = "isp_ahb", "cpp_func", "isp_axi", "dpu_mclk";
			clocks = <0xb 0x101 0xb 0x123 0xb 0xfe 0xb 0xf2>;
			compatible = "asr,mars11cpp";
			interrupt-names = "cpp";
			interrupts = <0x0 0x44 0x4>;
			power-domains = <0x22 0x3>;
			reg = <0x0 0xc02f0000 0x0 0x7fff>;
			reg-names = "cpp";
			status = "okay";
		};

		csiphy@d4206000 {
			asr,bifmode-enable;
			cell-index = <0x2>;
			clock-names = "csi_dphy";
			clocks = <0xb 0x104>;
			compatible = "asr,csi-dphy";
			phandle = <0x33>;
			reg = <0x0 0xd4206000 0x0 0x13f>;
			reg-names = "csiphy-regs";
			status = "okay";
		};

		csiphy@d420a000 {
			cell-index = <0x0>;
			clock-names = "csi_dphy";
			clocks = <0xb 0x102>;
			compatible = "asr,csi-dphy";
			phandle = <0x32>;
			reg = <0x0 0xd420a000 0x0 0x13f>;
			reg-names = "csiphy-regs";
			status = "okay";
		};

		csiphy@d420a800 {
			cell-index = <0x1>;
			clock-names = "csi_dphy";
			clocks = <0xb 0x103>;
			compatible = "asr,csi-dphy";
			reg = <0x0 0xd420a800 0x0 0x13f>;
			reg-names = "csiphy-regs";
			status = "disable";
		};

		dc@d4209000 {
			#address-cells = <0x2>;
			#size-cells = <0x2>;
			clock-names = "pxclk", "aclk", "busclk", "hbusclk", "ahbclk";
			clocks = <0xb 0x12b 0xb 0x12c 0xb 0x12d 0xb 0x12e 0xb 0x169>;
			compatible = "asr,dc";
			enable-qos = <0xd>;
			interrupts = <0x0 0x72 0x4>;
			lcd-panel = "lcd_gc9307_spi";
			lpm-period = <0x7d0>;
			lpm-qos = <0x7>;
			pinctrl-0 = <0x34>;
			pinctrl-1 = <0x35>;
			pinctrl-2 = <0x36>;
			pinctrl-names = "qspi", "3line2lane", "4line1lane";
			reg = <0x0 0xd4209000 0x0 0x210>;
			reg-names = "dc";
			status = "ok";
			vdd_2v8-supply = <0x2c>;
		};

		ddr_fc@c0000000 {
			#cooling-cells = <0x2>;
			clocks = <0xb 0xb4>;
			compatible = "asr,ddr-fc";
			enable_ipa_vmin_control;
			interrupts = <0x0 0x63 0x4>;
			reg = <0x0 0xc0000000 0x0 0x1800>;
			status = "okay";
			trfc = <0x0 0x0 0x0 0x0>;
		};

		ddraxi_mon@c0058500 {
			compatible = "asr,ddraxi-mon";
			reg = <0x0 0xc0058500 0x0 0x80>;
			status = "okay";
		};

		display-subsystem {
			compatible = "asr,saturn-le";
			hw_ver = <0x2>;
			ports = <0x28>;
			reg = <0x0 0xc0340000 0x0 0x2a000 0x0 0xc0300300 0x0 0x40>;
		};

		dphy2@d421a800 {
			#address-cells = <0x1>;
			#size-cells = <0x0>;
			compatible = "asr,dsi2-phy";
			dev-id = <0x2>;
			ip = "asr-dphy";
			reg = <0x0 0xd421a800 0x0 0x200>;
			status = "ok";

			port@1 {
				reg = <0x1>;

				endpoint {
					phandle = <0x2d>;
					remote-endpoint = <0x30>;
				};
			};
		};

		dpu_online2@c0340000 {
			asr-dpu-auto-fc;
			asr-dpu-min-mclk = <0x2710000>;
			clock-names = "pxclk", "mclk", "hclk", "escclk", "bitclk";
			clocks = <0xb 0xf0 0xb 0xf2 0xb 0xf1 0xb 0xf5 0xb 0xf6>;
			compatible = "asr,dpu-online2";
			enable-qos = <0xd>;
			interrupt-names = "ONLINE_IRQ", "OFFLINE_IRQ";
			interrupts = <0x0 0x4a 0x4 0x0 0x49 0x4>;
			ip = "asr-saturn";
			lpm-period = <0x7d0>;
			lpm-qos = <0x7>;
			memory-region = <0x29>;
			phandle = <0x28>;
			pipeline-id = <0x2>;
			power-domains = <0x22 0x2>;
			status = "okay";

			endpoint@0 {
				phandle = <0x2e>;
				remote-endpoint = <0x2a>;
			};

			endpoint@1 {
				phandle = <0x2f>;
				remote-endpoint = <0x2b>;
			};
		};

		dsi2@d421a800 {
			#address-cells = <0x1>;
			#size-cells = <0x0>;
			compatible = "asr,dsi2-host";
			dev-id = <0x2>;
			interrupts = <0x0 0x4f 0x4>;
			ip = "synopsys-dhost";
			reg = <0x0 0xd421a800 0x0 0x200>;
			status = "ok";

			panel2@0 {
				compatible = "asr,mipi-panel2";
				force-attached = "lcd_dummy_mipi";
				gpios-dc = <0x4f>;
				gpios-reset = <0x1>;
				id = <0x2>;
				reg = <0x0>;
				status = "ok";
				vdd_2v8-supply = <0x2c>;
			};

			ports {
				#address-cells = <0x1>;
				#size-cells = <0x0>;

				port@0 {
					reg = <0x0>;

					endpoint {
						phandle = <0x30>;
						remote-endpoint = <0x2d>;
					};
				};

				port@1 {
					reg = <0x1>;

					endpoint {
						phandle = <0x2a>;
						remote-endpoint = <0x2e>;
					};
				};
			};
		};

		ehci@c0900100 {
			asr,ehci-name = "mv-ehci";
			asr,extern-attr = <0x3>;
			asr,otg-force-a-bus-req;
			asr,udc-mode = <0x1>;
			clocks = <0xb 0xe6>;
			compatible = "asrci,mv-ehci";
			interrupts = <0x0 0x59 0x4>;
			phy-names = "usb-otg", "usb-phy";
			phys = <0x15 0x13>;
			reg = <0x0 0xc0900100 0x0 0x4000>;
			status = "okay";
		};

		extcon_asrci@d428287c {
			clocks = <0xb 0xe6>;
			compatible = "asrci,vbus-id";
			interrupts = <0x0 0x5a 0x4>;
			lpm-qos = <0x7>;
			phandle = <0x14>;
			reg = <0x0 0xd428287c 0x0 0x4 0x0 0xd4282918 0x0 0x4>;
			reg-names = "reg_pmuap", "pin_state";
			status = "okay";
		};

		fb@c0340000 {
			compatible = "asr,asrfb";
			interrupt-names = "ONLINE_IRQ", "OFFLINE_IRQ";
			interrupts = <0x0 0x4a 0x4 0x0 0x49 0x4>;
			reg = <0x0 0xc0340000 0x0 0x2a000>;
			status = "ok";
		};

		fixed-regulator-camera-af-2v8 {
			compatible = "regulator-fixed";
			enable-active-high;
			gpio = <0x12 0x2a 0x0>;
			phandle = <0x3b>;
			regulator-max-microvolt = <0x2ab980>;
			regulator-min-microvolt = <0x2ab980>;
			regulator-name = "ext_ldo1";
			status = "okay";
		};

		fm@c0883c00 {
			compatible = "asr,fmradio";
			default-freq = <0x14e60>;
			reg = <0x0 0xc0883c00 0x0 0x108>;
			status = "disabled";
		};

		gpu@c0500000 {
			#cooling-cells = <0x2>;
			clock-names = "clk_mali";
			clocks = <0xb 0xeb>;
			compatible = "arm,mali-midgard", "syscon";
			dvfs-freq1 = <0x98580>;
			interrupt-names = "JOB", "MMU", "GPU";
			interrupts = <0x0 0x3c 0x4 0x0 0x3e 0x4 0x0 0x3b 0x4>;
			ipa-model = "mali-simple-power-model";
			operating-points-v2 = <0x31>;
			power-domains = <0x22 0x1>;
			poweron-freq = <0x64000>;
			reg = <0x0 0xc0500000 0x0 0x80000>;
			status = "disable";
			system-coherency = <0x1f>;

			power_model {
				compatible = "arm,mali-simple-power-model";
				dynamic-coefficient = <0x77a>;
				static-coefficient = <0x77394>;
				thermal-zone = "gpu";
				ts = <0x34cdc9 0xffff6f16 0xffffff53 0x15>;
			};
		};

		imggpu@c0500000 {
			#cooling-cells = <0x2>;
			clock-names = "clk_rgx";
			clocks = <0xb 0xeb>;
			compatible = "img,rgx";
			interrupt-names = "rgxirq";
			interrupts = <0x0 0x3b 0x4>;
			operating-points-v2 = <0x31>;
			phandle = <0x39>;
			power-domains = <0x22 0x1>;
			reg = <0x0 0xc0500000 0x0 0x100000>;
			reg-names = "rgxregs";
			status = "okay";

			power_model {
				compatible = "img,pvr-simple-power-model";
				dynamic-coefficient = <0x13>;
				static-coefficient = <0x184>;
				thermal-zone = "gpu";
				ts = <0x34cdc9 0xffff6f16 0xffffff53 0x15>;
			};
		};

		isp@C0230000 {
			clock-names = "isp_ahb", "isp_func", "isp_axi", "dpu_mclk";
			clocks = <0xb 0x101 0xb 0xff 0xb 0xfe 0xb 0xf2>;
			compatible = "asr,mars11isp";
			interrupt-names = "feisp-irq", "feisp-dma-irq";
			interrupts = <0x0 0x3f 0x4 0x0 0x45 0x4>;
			power-domains = <0x22 0x3>;
			reg = <0x0 0xc0230000 0x0 0x12700>;
			reg-names = "isp";
			status = "okay";
		};

		jpu@c02f8000 {
			clock-names = "cclk", "aclk", "iclk", "fclk", "sclk";
			clocks = <0xb 0xfa 0xb 0xf2 0xb 0xfe 0xb 0xff 0xb 0x101>;
			compatible = "chip-media, jpu";
			interrupts = <0x0 0x47 0x4>;
			jpu,cclk-default-frequency = <0x2498e580>;
			jpu,cclk-max-frequency = <0x0 0x3b9aca00>;
			jpu,cclk-min-frequency = <0x1860d840>;
			jpu,chip-id = <0x0>;
			page-size = <0x4>;
			power-domains = <0x22 0x3>;
			reg = <0x0 0xc02f8000 0x0 0x700>;
			status = "okay";
		};

		linlon-v5@c0980000 {
			#cooling-cells = <0x2>;
			clocks = <0xb 0xed>;
			compatible = "arm china,linlon-v5", "syscon";
			interrupt-parent = <0x1>;
			interrupts = <0x0 0x3a 0x4>;
			power-domains = <0x22 0x0>;
			reg = <0x0 0xc0980000 0x0 0x10000>;
			status = "okay";
		};

		lz4@d8480000 {
			clock-names = "lz4";
			clocks = <0xb 0x10d>;
			compatible = "asr,lz4";
			interrupts = <0x0 0x67 0x4>;
			lpm-qos = <0x7>;
			reg = <0x0 0xd8480000 0x0 0x80000>;
			status = "okay";
		};

		opp_table0 {
			compatible = "operating-points-v2";
			phandle = <0x31>;

			opp153600000 {
				opp-hz = <0x0 0x927c000>;
				opp-microvolt = <0xc3500>;
			};

			opp307200000 {
				opp-hz = <0x0 0x124f8000>;
				opp-microvolt = <0xc3500>;
			};

			opp491520000 {
				opp-hz = <0x0 0x1d4c0000>;
				opp-microvolt = <0xc3500>;
			};

			opp614400000 {
				opp-hz = <0x0 0x249f0000>;
				opp-microvolt = <0xdbba0>;
			};

			opp76800000 {
				opp-hz = <0x0 0x493e000>;
				opp-microvolt = <0xc3500>;
			};

			opp819200000 {
				opp-hz = <0x0 0x30d40000>;
				opp-microvolt = <0xdbba0>;
			};
		};

		otg@c0900100 {
			#phy-cells = <0x0>;
			asr,extern-attr = <0x3>;
			asr,otg-force-a-bus-req;
			asr,otg-name = "mv-otg";
			asr,udc-mode = <0x1>;
			clocks = <0xb 0xe6>;
			compatible = "asrci,mv-otg";
			extcon = <0x14>;
			lpm-qos = <0x7>;
			phandle = <0x15>;
			phy-names = "usb-phy";
			phys = <0x13>;
			reg = <0x0 0xc0900100 0x0 0x4000 0x0 0xc0940000 0x0 0x200>;
			status = "okay";
		};

		plat-cam {
			#address-cells = <0x2>;
			#size-cells = <0x2>;
			compatible = "asr,plat-cam", "simple-bus";
			status = "okay";
		};

		thermal-zones {

			cpu_cluster {
				polling-delay = <0x0>;
				polling-delay-passive = <0x0>;
				sustainable-power = <0x0>;
				thermal-sensors = <0x37 0x3>;
			};

			cpu_core {
				polling-delay = <0x0>;
				polling-delay-passive = <0x0>;
				sustainable-power = <0x0>;
				thermal-sensors = <0x37 0x4>;

				trips {

					cpu-trip {
						hysteresis = <0x1388>;
						temperature = <0x15f90>;
						type = "passive";
					};
				};
			};

			gpu {
				polling-delay = <0x0>;
				polling-delay-passive = <0x0>;
				sustainable-power = <0x0>;
				thermal-sensors = <0x37 0x2>;
			};

			local {
				polling-delay = <0x0>;
				polling-delay-passive = <0x0>;
				sustainable-power = <0x0>;
				thermal-sensors = <0x37 0x0>;
			};

			pmic-temp {
				polling-delay = <0x0>;
				polling-delay-passive = <0x0>;
				sustainable-power = <0x0>;
				thermal-sensors = <0x3a 0x0>;
			};

			soc_max {
				polling-delay = <0x3e8>;
				polling-delay-passive = <0xc>;
				sustainable-power = <0xbb8>;
				thermal-sensors = <0x37 0xa>;

				cooling-maps {

					map0 {
						contribution = <0x400>;
						cooling-device = <0x2 0xffffffff 0xffffffff 0x3 0xffffffff 0xffffffff 0x4 0xffffffff 0xffffffff 0x5 0xffffffff 0xffffffff>;
						trip = <0x38>;
					};

					map1 {
						contribution = <0x400>;
						cooling-device = <0x39 0xffffffff 0xffffffff>;
						trip = <0x38>;
					};
				};

				trips {

					trip-point0 {
						hysteresis = <0x1388>;
						temperature = <0x19a28>;
						type = "critical";
					};

					trip-point1 {
						hysteresis = <0x1388>;
						temperature = <0x157c0>;
						type = "hot";
					};

					trip-point2 {
						hysteresis = <0x1388>;
						phandle = <0x38>;
						temperature = <0x13880>;
						type = "passive";
					};

					trip-point4 {
						hysteresis = <0xbb8>;
						temperature = <0xc350>;
						type = "passive";
					};
				};
			};

			top {
				polling-delay = <0x0>;
				polling-delay-passive = <0x0>;
				sustainable-power = <0x0>;
				thermal-sensors = <0x37 0x1>;
			};
		};

		touch@0 {
			compatible = "mediatek,touch";
			status = "disabled";
		};

		udc@c0900100 {
			asr,extern-attr = <0x3>;
			asr,otg-force-a-bus-req;
			asr,udc-mode = <0x1>;
			asr,udc-name = "mv-udc";
			clocks = <0xb 0xe6>;
			compatible = "asrci,mv-udc";
			extcon = <0x14>;
			interrupts = <0x0 0x59 0x4>;
			lpm-qos = <0x7>;
			phy-names = "usb-otg", "usb-phy";
			phys = <0x15 0x13>;
			reg = <0x0 0xc0900100 0x0 0x4000 0x0 0xc0900080 0x0 0x20>;
			reg-names = "reg_cap", "reg_timer";
			status = "okay";
		};

		usbphy@c0940000 {
			#phy-cells = <0x0>;
			asr,phy-name = "mv-usb-phy";
			asr,pll-lock-bypass;
			clocks = <0xb 0xe6>;
			compatible = "asrci,usb2-phy";
			phandle = <0x13>;
			reg = <0x0 0xc0940000 0x0 0x200>;
			status = "okay";
		};

		v2d@c0100000 {
			clock-names = "v2d-io", "v2d-core";
			clocks = <0xb 0xf2 0xb 0x114>;
			compatible = "asr,asr_v2d";
			interrupts = <0x0 0x46 0x4>;
			iommus = <0x16 0x0>;
			reg = <0x0 0xc0100000 0x0 0xc00>;
			reg-names = "v2dreg";
			status = "okay";
		};

		vi@C0230000 {
			clock-names = "isp_ahb", "isp_func", "isp_axi", "dpu_mclk";
			clocks = <0xb 0x101 0xb 0xff 0xb 0xfe 0xb 0xf2>;
			compatible = "asr,mars11vi";
			interrupt-names = "feisp-irq", "feisp-dma-irq", "ccic1-irq", "ccic2-irq", "ccic3-irq";
			interrupts = <0x0 0x3f 0x4 0x0 0x45 0x4 0x0 0x41 0x4 0x0 0x43 0x4 0x0 0x43 0x4>;
			power-domains = <0x22 0x3>;
			reg = <0x0 0xc0230000 0x0 0x14000 0x0 0xd420a000 0x0 0x3ff 0x0 0xd4206000 0x0 0x3ff 0x0 0xd4206000 0x0 0x3ff>;
			reg-names = "vi", "ccic1", "ccic2", "ccic3";
			status = "okay";
		};

		wb0 {
			compatible = "asr,wb0";
			dev-id = <0x2>;
			status = "ok";

			ports {
				#address-cells = <0x1>;
				#size-cells = <0x0>;

				port@0 {
					reg = <0x0>;

					endpoint {
						phandle = <0x2b>;
						remote-endpoint = <0x2f>;
					};
				};
			};
		};
	};

	usim1 {
		compatible = "asr,usim1";
		edge-wakeup-gpio = <0x50>;
		pinctrl-0 = <0x46>;
		pinctrl-names = "default";
		status = "ok";
	};

	usim2 {
		compatible = "asr,usim2";
		edge-wakeup-gpio = <0x51>;
		status = "ok";
	};
};
